VERSION "HNNBNNNYNNNNNNNNNNNNNNNNNNNNNNNNNNNNNNNNNN/4>*%%/4/'%**4NNN///"

NS_ :

BS_:

BU_: Motor DispEngine PedalUnit GearBox Gateway EngineControl Display DashBoard ABS

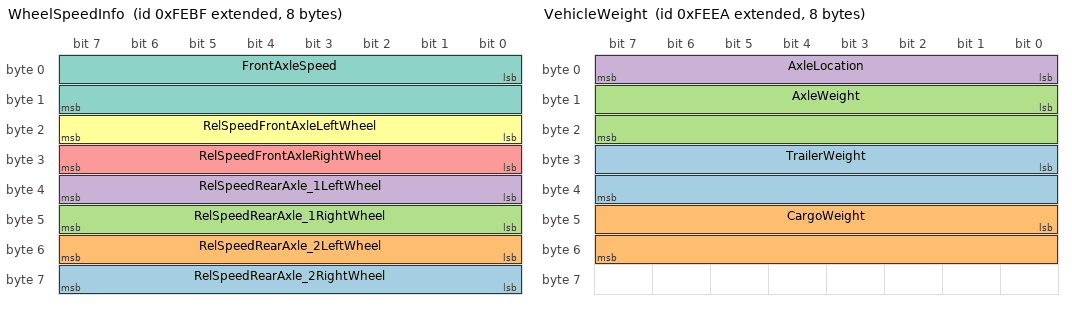
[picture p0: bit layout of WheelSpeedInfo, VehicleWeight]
BO_ 2147548863 WheelSpeedInfo: 8 Vector__XXX
 SG_ RelSpeedRearAxle_2RightWheel : 56|8@1+ (0.0625,-7.8125) [-7.8125|7.8125] "km/h" Vector__XXX
 SG_ RelSpeedRearAxle_2LeftWheel : 48|8@1+ (0.0625,-7.8125) [-7.8125|7.8125] "km/h" Vector__XXX
 SG_ RelSpeedRearAxle_1RightWheel : 40|8@1+ (0.0625,-7.8125) [-7.8125|7.8125] "km/h" Vector__XXX
 SG_ RelSpeedRearAxle_1LeftWheel : 32|8@1+ (0.0625,-7.8125) [-7.8125|7.8125] "km/h" Vector__XXX
 SG_ RelSpeedFrontAxleRightWheel : 24|8@1+ (0.0625,-7.8125) [-7.8125|7.8125] "km/h" Vector__XXX
 SG_ RelSpeedFrontAxleLeftWheel : 16|8@1+ (0.0625,-7.8125) [-7.8125|7.8125] "km/h" Vector__XXX
 SG_ FrontAxleSpeed : 0|16@1+ (0.00390625,0) [0|251] "km/" Vector__XXX

BO_ 2147548927 WaterInFuelInd: 8 Vector__XXX
 SG_ WaterInFuelIndicator : 0|8@1+ (1,0) [0|255] "" Vector__XXX

BO_ 2147548906 VehicleWeight: 8 Vector__XXX
 SG_ TrailerWeight : 24|16@1+ (2,0) [0|128510] "kg" Vector__XXX
 SG_ CargoWeight : 40|16@1+ (2,0) [0|128510] "kg" Vector__XXX
 SG_ AxleWeight : 8|16@1+ (0.5,0) [0|32127.5] "kg" Vector__XXX
 SG_ AxleLocation : 0|8@1+ (1,0) [0|255] "" Vector__XXX

BO_ 2147548915 VehiclePosition: 8 Vector__XXX
 SG_ Longitude : 32|32@1+ (1E-007,-210) [-210|211.108] "degr" Vector__XXX
 SG_ Latitude : 0|32@1+ (1E-007,-210) [-210|211.108] "degr" Vector__XXX

BO_ 2147548903 VehicleHours: 8 Vector__XXX
 SG_ TotalVehicleHours : 0|32@1+ (0.05,0) [0|210554000] "h" Vector__XXX
 SG_ TotalPowerTakeoffHours : 32|32@1+ (0.05,0) [0|210554000] "h" Vector__XXX

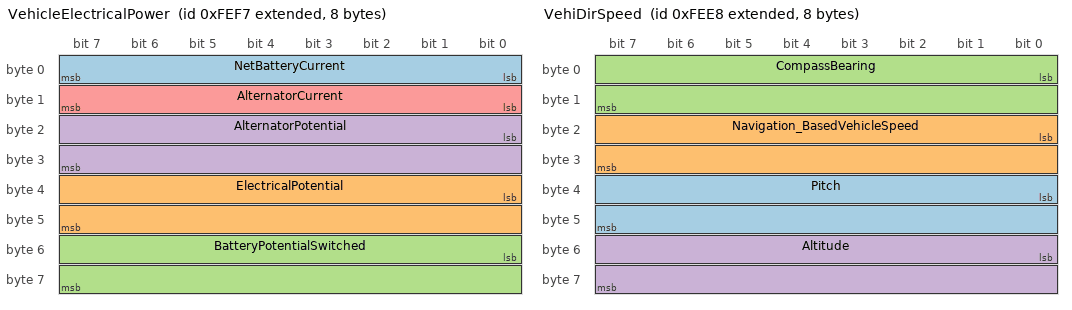
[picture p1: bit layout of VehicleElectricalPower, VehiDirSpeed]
BO_ 2147548919 VehicleElectricalPower: 8 Vector__XXX
 SG_ NetBatteryCurrent : 0|8@1+ (1,-125) [-125|125] "A" Vector__XXX
 SG_ ElectricalPotential : 32|16@1+ (0.05,0) [0|3212.75] "V" Vector__XXX
 SG_ BatteryPotentialSwitched : 48|16@1+ (0.05,0) [0|3212.75] "V" Vector__XXX
 SG_ AlternatorPotential : 16|16@1+ (0.05,0) [0|3212.75] "V" Vector__XXX
 SG_ AlternatorCurrent : 8|8@1+ (1,0) [0|250] "A" Vector__XXX

BO_ 2147548896 VehicleDistance: 8 Vector__XXX
 SG_ TripDistance : 0|32@1+ (0.125,0) [0|526385000] "km" Vector__XXX
 SG_ TotalVehicleDistance : 32|32@1+ (0.125,0) [0|526385000] "km" Vector__XXX

BO_ 2147548904 VehiDirSpeed: 8 Vector__XXX
 SG_ Pitch : 32|16@1+ (0.0078125,-200) [-200|302] "degr" Vector__XXX
 SG_ Navigation_BasedVehicleSpeed : 16|16@1+ (0.00390625,0) [0|251] "km/h" Vector__XXX
 SG_ CompassBearing : 0|16@1+ (0.0078125,0) [0|502] "degr" Vector__XXX
 SG_ Altitude : 48|16@1+ (0.125,0) [0|526385000] "km" Vector__XXX

BO_ 2147548893 Turbocharger: 8 Vector__XXX
 SG_ TurboSpeed : 8|16@1+ (4,0) [0|257020] "rpm" Vector__XXX
 SG_ TurboOilPressure : 0|8@1+ (4,0) [0|1000] "kPa" Vector__XXX

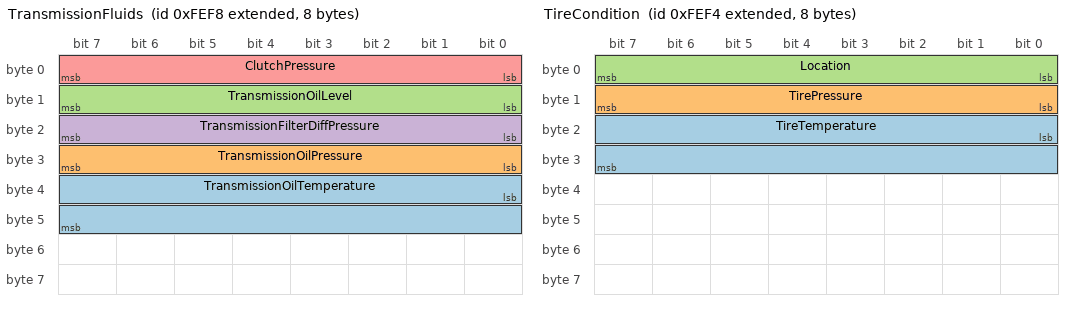
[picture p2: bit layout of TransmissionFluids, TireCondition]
BO_ 2147548920 TransmissionFluids: 8 Vector__XXX
 SG_ TransmissionOilTemperature : 32|16@1+ (0.03125,-273) [-273|1735] "°C" Vector__XXX
 SG_ TransmissionOilPressure : 24|8@1+ (16,0) [0|400] "kPa" Vector__XXX
 SG_ TransmissionOilLevel : 8|8@1+ (0.4,0) [0|100] "%" Vector__XXX
 SG_ TransmissionFilterDiffPressure : 16|8@1+ (2,0) [0|500] "kPa" Vector__XXX
 SG_ ClutchPressure : 0|8@1+ (16,0) [0|400] "kPa" Vector__XXX

BO_ 2147548898 TransmissionConfig: 15 Vector__XXX
 SG_ NumberOfReverseGearRatios : 0|8@1+ (1,0) [0|255] "" Vector__XXX
 SG_ NumberOfForwardGearRatios : 8|8@1+ (1,0) [0|255] "" Vector__XXX
 SG_ MiddleReverseGearRatio : 32|16@1+ (0.001,0) [0|64255] "" Vector__XXX
 SG_ MiddleForwardGearRatio : 88|16@1+ (0.001,0) [0|64255] "" Vector__XXX
 SG_ LowestReverseGearRatio : 48|16@1+ (0.001,0) [0|64255] "" Vector__XXX
 SG_ LowestForwardGearRatio : 104|16@1+ (0.001,0) [0|64255] "" Vector__XXX
 SG_ HighestReverseGearRatio : 16|16@1+ (0.001,0) [0|64255] "" Vector__XXX
 SG_ HighestForwardGearRatio : 72|16@1+ (0.001,0) [0|64255] "" Vector__XXX

BO_ 2147548916 TireCondition: 8 Vector__XXX
 SG_ TireTemperature : 16|16@1+ (0.03125,-273) [-273|1735] "°C" Vector__XXX
 SG_ TirePressure : 8|8@1+ (4,0) [0|1000] "kPa" Vector__XXX
 SG_ Location : 0|8@1+ (1,0) [0|255] "" Vector__XXX

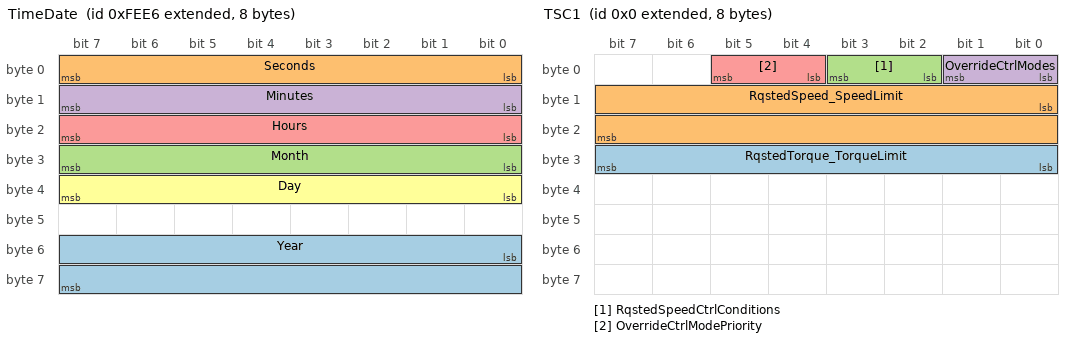
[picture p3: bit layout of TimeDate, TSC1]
BO_ 2147548902 TimeDate: 8 Vector__XXX
 SG_ Year : 48|16@1+ (1,1985) [1985|2235] "year" Vector__XXX
 SG_ Seconds : 0|8@1+ (0.25,0) [0|59.75] "s" Vector__XXX
 SG_ Month : 24|8@1+ (1,0) [1|12] "month" Vector__XXX
 SG_ Minutes : 8|8@1+ (1,0) [0|59] "min" Vector__XXX
 SG_ Hours : 16|8@1+ (1,0) [0|23] "h" Vector__XXX
 SG_ Day : 32|8@1+ (0.25,0) [0.25|31.75] "day" Vector__XXX

BO_ 2147483648 TSC1: 8 Vector__XXX
 SG_ RqstedTorque_TorqueLimit : 24|8@1+ (1,-125) [-125|125] "%" Vector__XXX
 SG_ RqstedSpeed_SpeedLimit : 8|16@1+ (0.125,0) [0|8031.88] "rpm" Vector__XXX
 SG_ RqstedSpeedCtrlConditions : 2|2@1+ (1,0) [0|3] "" Vector__XXX
 SG_ OverrideCtrlModes : 0|2@1+ (1,0) [0|3] "" Vector__XXX
 SG_ OverrideCtrlModePriority : 4|2@1+ (1,0) [0|3] "" Vector__XXX

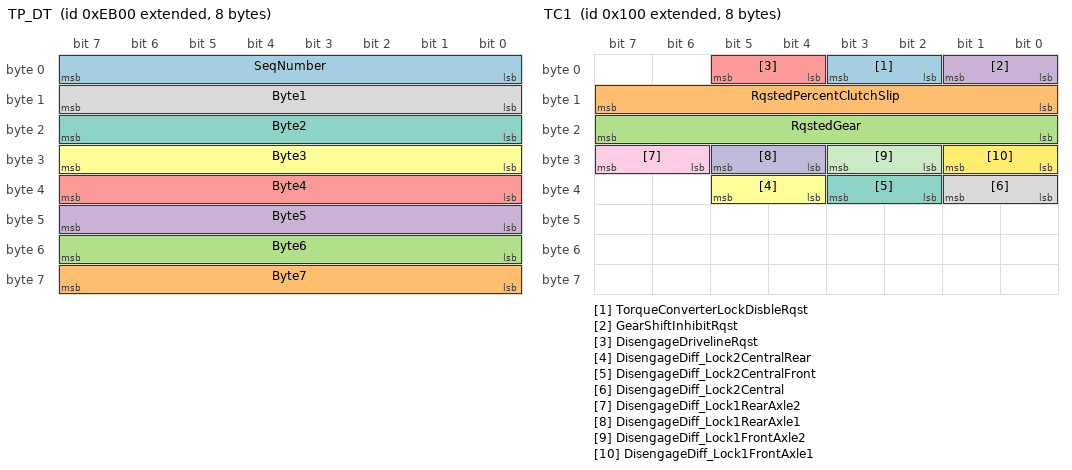
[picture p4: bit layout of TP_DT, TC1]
BO_ 2147543808 TP_DT: 8 Vector__XXX
 SG_ SeqNumber : 0|8@1+ (1,0) [1|255] "" Vector__XXX
 SG_ Byte7 : 56|8@1+ (1,0) [0|255] "" Vector__XXX
 SG_ Byte6 : 48|8@1+ (1,0) [0|255] "" Vector__XXX
 SG_ Byte5 : 40|8@1+ (1,0) [0|255] "" Vector__XXX
 SG_ Byte4 : 32|8@1+ (1,0) [0|255] "" Vector__XXX
 SG_ Byte3 : 24|8@1+ (1,0) [0|255] "" Vector__XXX
 SG_ Byte2 : 16|8@1+ (1,0) [0|255] "" Vector__XXX
 SG_ Byte1 : 8|8@1+ (1,0) [0|255] "" Vector__XXX

BO_ 2147544064 TP_CM: 8 Vector__XXX
 SG_ SendPackets m17 : 8|8@1+ (1,0) [0|255] "" Vector__XXX
 SG_ RtsNoPackets m16 : 24|8@1+ (1,0) [1|255] "" Vector__XXX
 SG_ RtsMsgSize m16 : 8|16@1+ (1,0) [9|1785] "" Vector__XXX
 SG_ PGNumber : 40|24@1+ (1,0) [0|16777200] "" Vector__XXX
 SG_ NextPacket m17 : 16|8@1+ (1,0) [1|255] "" Vector__XXX
 SG_ ControlByte M : 0|8@1+ (1,0) [0|255] "" Vector__XXX
 SG_ BamNoPackets m32 : 24|8@1+ (1,0) [1|255] "" Vector__XXX
 SG_ BamMsgSize m32 : 8|16@1+ (1,0) [9|1785] "" Vector__XXX
 SG_ AckNoPackets m19 : 24|8@1+ (1,0) [1|255] "" Vector__XXX
 SG_ AckMsgSize m19 : 8|16@1+ (1,0) [9|1785] "" Vector__XXX

BO_ 2147483904 TC1: 8 Vector__XXX
 SG_ TorqueConverterLockDisbleRqst : 2|2@1+ (1,0) [0|3] "" Vector__XXX
 SG_ RqstedPercentClutchSlip : 8|8@1+ (0.4,0) [0|100] "%" Vector__XXX
 SG_ RqstedGear : 16|8@1+ (1,-125) [-125|125] "gear" Vector__XXX
 SG_ GearShiftInhibitRqst : 0|2@1+ (1,0) [0|3] "" Vector__XXX
 SG_ DisengageDrivelineRqst : 4|2@1+ (1,0) [0|3] "" Vector__XXX
 SG_ DisengageDiff_Lock2CentralRear : 36|2@1+ (1,0) [0|3] "" Vector__XXX
 SG_ DisengageDiff_Lock2CentralFront : 34|2@1+ (1,0) [0|3] "" Vector__XXX
 SG_ DisengageDiff_Lock2Central : 32|2@1+ (1,0) [0|3] "" Vector__XXX
 SG_ DisengageDiff_Lock1RearAxle2 : 30|2@1+ (1,0) [0|3] "" Vector__XXX
 SG_ DisengageDiff_Lock1RearAxle1 : 28|2@1+ (1,0) [0|3] "" Vector__XXX
 SG_ DisengageDiff_Lock1FrontAxle2 : 26|2@1+ (1,0) [0|3] "" Vector__XXX
 SG_ DisengageDiff_Lock1FrontAxle1 : 24|2@1+ (1,0) [0|3] "" Vector__XXX

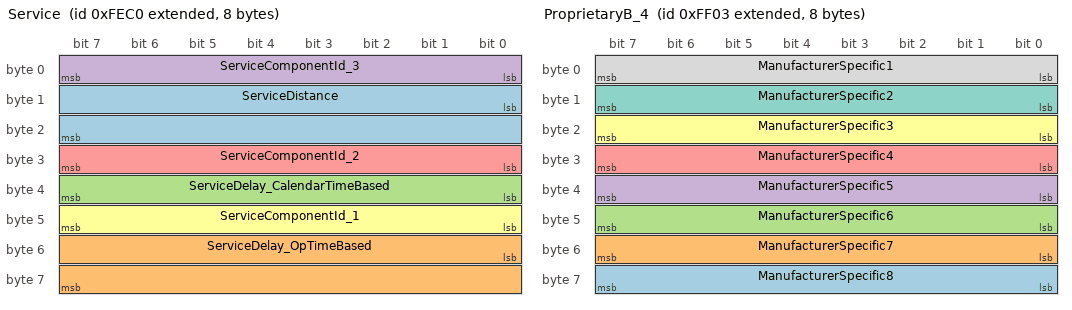
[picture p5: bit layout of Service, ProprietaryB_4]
BO_ 2147548864 Service: 8 Vector__XXX
 SG_ ServiceDistance : 8|16@1+ (5,-160635) [-160635|160640] "km" Vector__XXX
 SG_ ServiceDelay_OpTimeBased : 48|16@1+ (1,-32127) [-32127|32128] "h" Vector__XXX
 SG_ ServiceDelay_CalendarTimeBased : 32|8@1+ (1,-125) [-125|125] "weeks" Vector__XXX
 SG_ ServiceComponentId_3 : 0|8@1+ (1,0) [0|255] "" Vector__XXX
 SG_ ServiceComponentId_2 : 24|8@1+ (1,0) [0|255] "" Vector__XXX
 SG_ ServiceComponentId_1 : 40|8@1+ (1,0) [0|255] "" Vector__XXX

BO_ 2147548923 RetarderFluids: 8 Vector__XXX
 SG_ HydraulicRetarderPressure : 0|8@1+ (16,0) [0|4000] "kPa" Vector__XXX
 SG_ HydraulicRetarderOilTemp : 8|8@1+ (1,-40) [-40|210] "°C" Vector__XXX

BO_ 2147548897 RetarderConfig: 19 Vector__XXX
 SG_ RetarderType : 0|4@1+ (1,0) [0|15] "" Vector__XXX
 SG_ RetarderSpeedAtPt4 : 88|16@1+ (0.125,0) [0|8031.88] "rpm" Vector__XXX
 SG_ RetarderSpeedAtPt3 : 64|16@1+ (0.125,0) [0|8031.88] "rpm" Vector__XXX
 SG_ RetarderSpeedAtPeakTorquePt5 : 112|16@1+ (0.125,0) [0|8031.88] "rpm" Vector__XXX
 SG_ RetarderSpeedAtIdlePt1 : 16|16@1+ (0.125,0) [0|8031.88] "rpm" Vector__XXX
 SG_ RetarderLocation : 4|4@1+ (1,0) [0|15] "" Vector__XXX
 SG_ RetarderCtrlMethod : 8|8@1+ (1,0) [0|250] "step" Vector__XXX
 SG_ ReferenceRetarderTorque : 128|16@1+ (1,0) [0|64255] "Nm" Vector__XXX
 SG_ PercentTorqueAtPt4 : 104|8@1+ (1,-125) [-125|125] "%" Vector__XXX
 SG_ PercentTorqueAtPt3 : 80|8@1+ (1,-125) [-125|125] "%" Vector__XXX
 SG_ PercentTorqueAtPeakTorquePt5 : 144|8@1+ (1,-125) [-125|125] "%" Vector__XXX
 SG_ PercentTorqueAtMaxSpeedPt2 : 56|8@1+ (1,-125) [-125|125] "%" Vector__XXX
 SG_ PercentTorqueAtIdlePt1 : 32|8@1+ (1,-125) [-125|125] "%" Vector__XXX
 SG_ MaximumRetarderSpeedPt2 : 40|16@1+ (0.125,0) [0|8031.88] "rpm" Vector__XXX

BO_ 2147543552 RequestPGN: 3 Vector__XXX
 SG_ RqstedPGN : 0|24@1+ (1,0) [0|16777200] "" Vector__XXX

BO_ 2147548931 ProprietaryB_4: 8 Vector__XXX
 SG_ ManufacturerSpecific8 : 56|8@1+ (1,0) [0|255] "" Vector__XXX
 SG_ ManufacturerSpecific7 : 48|8@1+ (1,0) [0|255] "" Vector__XXX
 SG_ ManufacturerSpecific6 : 40|8@1+ (1,0) [0|255] "" Vector__XXX
 SG_ ManufacturerSpecific5 : 32|8@1+ (1,0) [0|255] "" Vector__XXX
 SG_ ManufacturerSpecific4 : 24|8@1+ (1,0) [0|255] "" Vector__XXX
 SG_ ManufacturerSpecific3 : 16|8@1+ (1,0) [0|255] "" Vector__XXX
 SG_ ManufacturerSpecific2 : 8|8@1+ (1,0) [0|255] "" Vector__XXX
 SG_ ManufacturerSpecific1 : 0|8@1+ (1,0) [0|255] "" Vector__XXX

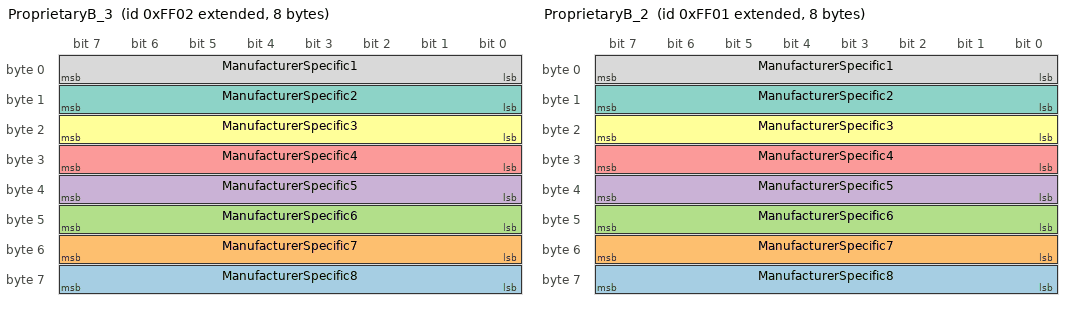
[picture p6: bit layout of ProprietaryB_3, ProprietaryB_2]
BO_ 2147548930 ProprietaryB_3: 8 Vector__XXX
 SG_ ManufacturerSpecific8 : 56|8@1+ (1,0) [0|255] "" Vector__XXX
 SG_ ManufacturerSpecific7 : 48|8@1+ (1,0) [0|255] "" Vector__XXX
 SG_ ManufacturerSpecific6 : 40|8@1+ (1,0) [0|255] "" Vector__XXX
 SG_ ManufacturerSpecific5 : 32|8@1+ (1,0) [0|255] "" Vector__XXX
 SG_ ManufacturerSpecific4 : 24|8@1+ (1,0) [0|255] "" Vector__XXX
 SG_ ManufacturerSpecific3 : 16|8@1+ (1,0) [0|255] "" Vector__XXX
 SG_ ManufacturerSpecific2 : 8|8@1+ (1,0) [0|255] "" Vector__XXX
 SG_ ManufacturerSpecific1 : 0|8@1+ (1,0) [0|255] "" Vector__XXX

BO_ 2147548929 ProprietaryB_2: 8 Vector__XXX
 SG_ ManufacturerSpecific8 : 56|8@1+ (1,0) [0|255] "" Vector__XXX
 SG_ ManufacturerSpecific7 : 48|8@1+ (1,0) [0|255] "" Vector__XXX
 SG_ ManufacturerSpecific6 : 40|8@1+ (1,0) [0|255] "" Vector__XXX
 SG_ ManufacturerSpecific5 : 32|8@1+ (1,0) [0|255] "" Vector__XXX
 SG_ ManufacturerSpecific4 : 24|8@1+ (1,0) [0|255] "" Vector__XXX
 SG_ ManufacturerSpecific3 : 16|8@1+ (1,0) [0|255] "" Vector__XXX
 SG_ ManufacturerSpecific2 : 8|8@1+ (1,0) [0|255] "" Vector__XXX
 SG_ ManufacturerSpecific1 : 0|8@1+ (1,0) [0|255] "" Vector__XXX

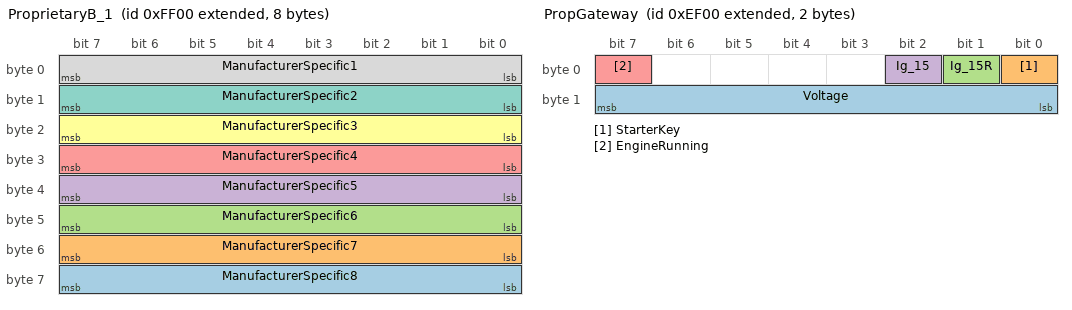
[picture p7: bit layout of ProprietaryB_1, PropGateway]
BO_ 2147548928 ProprietaryB_1: 8 Vector__XXX
 SG_ ManufacturerSpecific8 : 56|8@1+ (1,0) [0|255] "" Vector__XXX
 SG_ ManufacturerSpecific7 : 48|8@1+ (1,0) [0|255] "" Vector__XXX
 SG_ ManufacturerSpecific6 : 40|8@1+ (1,0) [0|255] "" Vector__XXX
 SG_ ManufacturerSpecific5 : 32|8@1+ (1,0) [0|255] "" Vector__XXX
 SG_ ManufacturerSpecific4 : 24|8@1+ (1,0) [0|255] "" Vector__XXX
 SG_ ManufacturerSpecific3 : 16|8@1+ (1,0) [0|255] "" Vector__XXX
 SG_ ManufacturerSpecific2 : 8|8@1+ (1,0) [0|255] "" Vector__XXX
 SG_ ManufacturerSpecific1 : 0|8@1+ (1,0) [0|255] "" Vector__XXX

BO_ 2147544832 PropGateway: 2 Vector__XXX
 SG_ Voltage : 8|8@1+ (0.1,0) [50|180] "V" Vector__XXX
 SG_ StarterKey : 0|1@1+ (1,0) [0|1] "" Vector__XXX
 SG_ Ig_15R : 1|1@1+ (1,0) [0|0] "" Vector__XXX
 SG_ Ig_15 : 2|1@1+ (1,0) [0|0] "" Vector__XXX
 SG_ EngineRunning : 7|1@1+ (1,0) [0|0] "" Vector__XXX

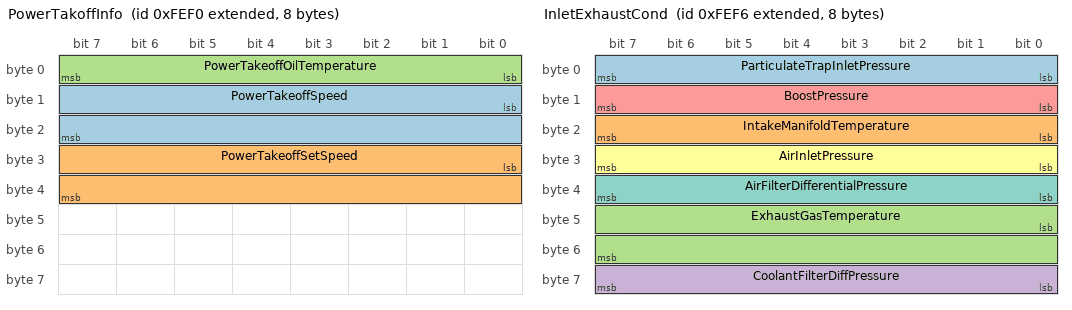
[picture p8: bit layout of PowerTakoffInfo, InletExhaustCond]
BO_ 2147548912 PowerTakoffInfo: 8 Vector__XXX
 SG_ PowerTakeoffSpeed : 8|16@1+ (0.125,0) [0|8031.88] "rpm" Vector__XXX
 SG_ PowerTakeoffSetSpeed : 24|16@1+ (0.125,0) [0|8031.88] "rpm" Vector__XXX
 SG_ PowerTakeoffOilTemperature : 0|8@1+ (1,-40) [-40|210] "°C" Vector__XXX

BO_ 2147548918 InletExhaustCond: 8 Vector__XXX
 SG_ ParticulateTrapInletPressure : 0|8@1+ (0.5,0) [0|125] "kPa" Vector__XXX
 SG_ IntakeManifoldTemperature : 16|8@1+ (1,-40) [-40|210] "°C" Vector__XXX
 SG_ ExhaustGasTemperature : 40|16@1+ (0.03125,-273) [-273|1735] "°C" Vector__XXX
 SG_ CoolantFilterDiffPressure : 56|8@1+ (0.5,0) [0|125] "kPa" Vector__XXX
 SG_ BoostPressure : 8|8@1+ (2,0) [0|500] "kPa" Vector__XXX
 SG_ AirInletPressure : 24|8@1+ (2,0) [0|500] "kPa" Vector__XXX
 SG_ AirFilterDifferentialPressure : 32|8@1+ (0.05,0) [0|12.5] "kPa" Vector__XXX

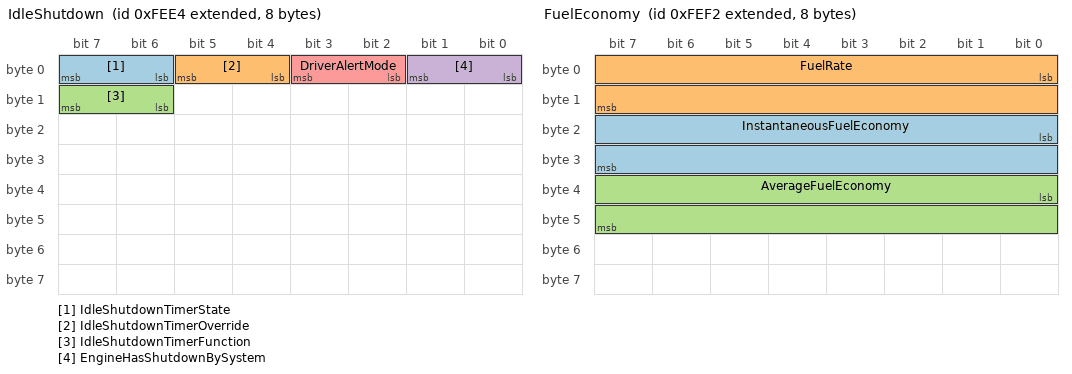
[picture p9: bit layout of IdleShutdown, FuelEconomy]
BO_ 2147548900 IdleShutdown: 8 Vector__XXX
 SG_ IdleShutdownTimerState : 6|2@1+ (1,0) [0|3] "" Vector__XXX
 SG_ IdleShutdownTimerOverride : 4|2@1+ (1,0) [0|3] "" Vector__XXX
 SG_ IdleShutdownTimerFunction : 14|2@1+ (1,0) [0|3] "" Vector__XXX
 SG_ EngineHasShutdownBySystem : 0|2@1+ (1,0) [0|3] "" Vector__XXX
 SG_ DriverAlertMode : 2|2@1+ (1,0) [0|3] "" Vector__XXX

BO_ 2147548892 IdleOperation: 8 Vector__XXX
 SG_ TotalIdleHours : 32|32@1+ (0.05,0) [0|210554000] "h" Vector__XXX
 SG_ TotalIdleFuelUsed : 0|32@1+ (0.5,0) [0|2105540000] "L" Vector__XXX

BO_ 2147548865 HiResVehicleDist: 8 Vector__XXX
 SG_ HighResolTripDistance : 32|32@1+ (5,0) [0|21055400] "km" Vector__XXX
 SG_ HighResolTotalVehicleDistance : 0|32@1+ (5,0) [0|21055400] "km" Vector__XXX

BO_ 2147548914 FuelEconomy: 8 Vector__XXX
 SG_ InstantaneousFuelEconomy : 16|16@1+ (0.00195312,0) [0|125.5] "km" Vector__XXX
 SG_ FuelRate : 0|16@1+ (0.05,0) [0|3212.75] "L/h" Vector__XXX
 SG_ AverageFuelEconomy : 32|16@1+ (0.00195312,0) [0|125.5] "km" Vector__XXX

BO_ 2147548905 FuelConsumption: 8 Vector__XXX
 SG_ TripFuel : 0|32@1+ (0.5,0) [0|2105540000] "L" Vector__XXX
 SG_ TotalFuelUsed : 32|32@1+ (0.5,0) [0|2105540000] "L" Vector__XXX

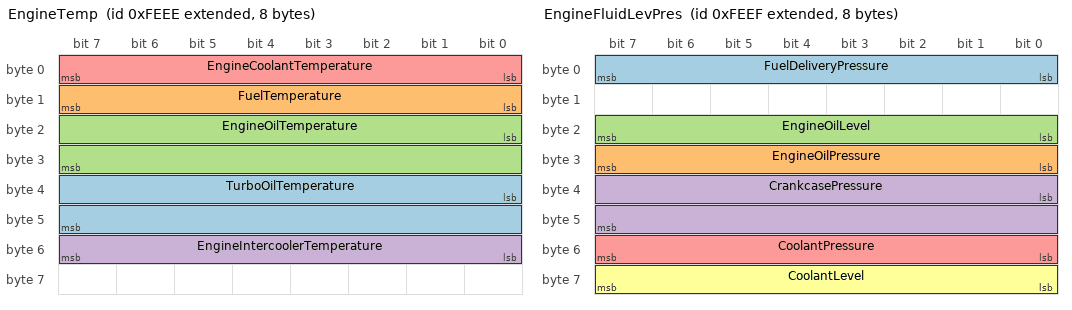
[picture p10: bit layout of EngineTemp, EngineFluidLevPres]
BO_ 2147548910 EngineTemp: 8 Vector__XXX
 SG_ TurboOilTemperature : 32|16@1+ (0.03125,-273) [-273|1735] "°C" Vector__XXX
 SG_ FuelTemperature : 8|8@1+ (1,-40) [-40|210] "°C" Vector__XXX
 SG_ EngineOilTemperature : 16|16@1+ (0.03125,-273) [-273|1735] "°C" Vector__XXX
 SG_ EngineIntercoolerTemperature : 48|8@1+ (1,-40) [-40|210] "°C" Vector__XXX
 SG_ EngineCoolantTemperature : 0|8@1+ (1,-40) [-40|210] "°C" Vector__XXX

BO_ 2147548901 EngineHoursRevolutions: 8 Vector__XXX
 SG_ TotalEngineRevolutions : 32|32@1+ (1000,0) [0|4.21108E+012] "r" Vector__XXX
 SG_ TotalEngineHours : 0|32@1+ (0.05,0) [0|210554000] "h" Vector__XXX

BO_ 2147548891 EngineFluidLevPres2: 8 Vector__XXX
 SG_ InjectorMeteringRailPressure : 16|16@1+ (0.00390625,0) [0|251] "MPa" Vector__XXX
 SG_ InjectionCtrlPressure : 0|16@1+ (0.00390625,0) [0|251] "MPa" Vector__XXX

BO_ 2147548911 EngineFluidLevPres: 8 Vector__XXX
 SG_ FuelDeliveryPressure : 0|8@1+ (4,0) [0|1000] "kPa" Vector__XXX
 SG_ EngineOilPressure : 24|8@1+ (4,0) [0|1000] "kPa" Vector__XXX
 SG_ EngineOilLevel : 16|8@1+ (0.4,0) [0|100] "%" Vector__XXX
 SG_ CrankcasePressure : 32|16@1+ (7812.5,-250) [-250|251.99] "kPa" Vector__XXX
 SG_ CoolantPressure : 48|8@1+ (2,0) [0|500] "kPa" Vector__XXX
 SG_ CoolantLevel : 56|8@1+ (0.4,0) [0|100] "%" Vector__XXX

BO_ 2147548899 EngineConfig: 28 Vector__XXX
 SG_ RqstedTorqueCtrlRangeUpperLimit : 216|8@1+ (1,-125) [-125|125] "%" Vector__XXX
 SG_ RqstedTorqueCtrlRangeLowerLimit : 208|8@1+ (1,-125) [-125|125] "%" Vector__XXX
 SG_ RqstedSpeedCtrlRangeUpperLimit : 200|8@1+ (10,0) [0|2500] "rpm" Vector__XXX
 SG_ RqstedSpeedCtrlRangeLowerLimit : 192|8@1+ (10,0) [0|2500] "rpm" Vector__XXX
 SG_ ReferenceEngineTorque : 152|16@1+ (1,0) [0|64255] "Nm" Vector__XXX
 SG_ PercentTorqueAtPt5 : 112|8@1+ (1,-125) [-125|125] "%" Vector__XXX
 SG_ PercentTorqueAtPt4 : 88|8@1+ (1,-125) [-125|125] "%" Vector__XXX
 SG_ PercentTorqueAtPt3 : 64|8@1+ (1,-125) [-125|125] "%" Vector__XXX
 SG_ PercentTorqueAtPt2 : 40|8@1+ (1,-125) [-125|125] "%" Vector__XXX
 SG_ PercentTorqueAtIdlePt1 : 16|8@1+ (1,-125) [-125|125] "%" Vector__XXX
 SG_ MaxMomentEngineOvrwrtTimeLimit : 184|8@1+ (0.1,0) [0|25] "s" Vector__XXX
 SG_ MaxMomentEngineOvrwrtSpeedPt7 : 168|16@1+ (0.125,0) [0|8031.88] "rpm" Vector__XXX
 SG_ GainOfEndspeedGovernor : 136|16@1+ (0.0007813,0) [0|50.2] "%" Vector__XXX
 SG_ EngineSpeedAtPt5 : 96|16@1+ (0.125,0) [0|8031.88] "rpm" Vector__XXX
 SG_ EngineSpeedAtPt4 : 72|16@1+ (0.125,0) [0|8031.88] "rpm" Vector__XXX
 SG_ EngineSpeedAtPt3 : 48|16@1+ (0.125,0) [0|8031.88] "rpm" Vector__XXX
 SG_ EngineSpeedAtPt2 : 24|16@1+ (0.125,0) [0|8031.88] "rpm" Vector__XXX
 SG_ EngineSpeedAtIdlePt1 : 0|16@1+ (0.125,0) [0|8031.88] "rpm" Vector__XXX
 SG_ EngineSpeedAtHighIdlePt6 : 120|16@1+ (0.125,0) [0|8031.88] "rpm" Vector__XXX

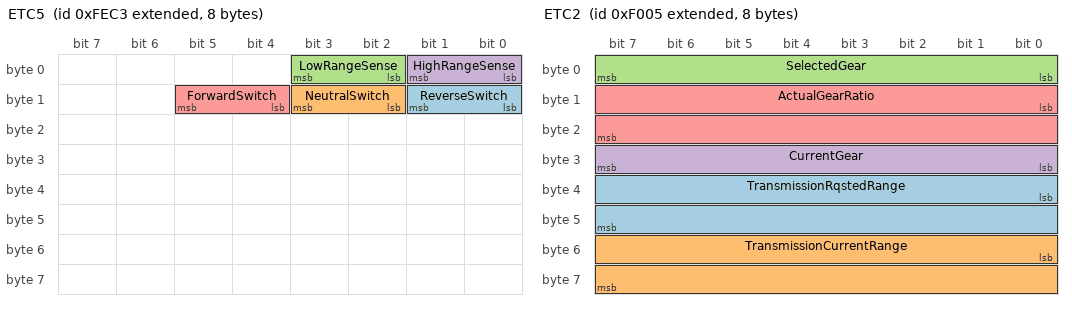
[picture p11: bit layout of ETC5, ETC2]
BO_ 2147548867 ETC5: 8 Vector__XXX
 SG_ ReverseSwitch : 8|2@1+ (1,0) [0|3] "" Vector__XXX
 SG_ NeutralSwitch : 10|2@1+ (1,0) [0|3] "" Vector__XXX
 SG_ LowRangeSense : 2|2@1+ (1,0) [0|3] "" Vector__XXX
 SG_ HighRangeSense : 0|2@1+ (1,0) [0|3] "" Vector__XXX
 SG_ ForwardSwitch : 12|2@1+ (1,0) [0|3] "" Vector__XXX

BO_ 2147548869 ETC4: 8 Vector__XXX
 SG_ TransmissionSynchroClutchVal : 0|8@1+ (0.4,0) [0|100] "%" Vector__XXX
 SG_ TransmissionSynchroBrakeVal : 8|8@1+ (0.4,0) [0|100] "%" Vector__XXX

BO_ 2147548871 ETC3: 8 Vector__XXX
 SG_ SplitterIndirectActuator : 38|2@1+ (1,0) [0|3] "" Vector__XXX
 SG_ SplitterDirectActuator : 36|2@1+ (1,0) [0|3] "" Vector__XXX
 SG_ ShiftFingerRailPosition : 8|8@1+ (0.4,0) [0|100] "%" Vector__XXX
 SG_ ShiftFingerGearPosition : 0|8@1+ (0.4,0) [0|100] "%" Vector__XXX
 SG_ RangeLowActuator : 34|2@1+ (1,0) [0|3] "" Vector__XXX
 SG_ RangeHighActuator : 32|2@1+ (1,0) [0|3] "" Vector__XXX
 SG_ RailActuator_2 : 28|2@1+ (1,0) [0|3] "" Vector__XXX
 SG_ RailActuator_1 : 24|2@1+ (1,0) [0|3] "" Vector__XXX
 SG_ NeutralIndicator : 16|2@1+ (1,0) [0|3] "" Vector__XXX
 SG_ LockupClutchActuator : 42|2@1+ (1,0) [0|3] "" Vector__XXX
 SG_ InertiaBrakeActuator : 46|2@1+ (1,0) [0|3] "" Vector__XXX
 SG_ GearActuator_2 : 30|2@1+ (1,0) [0|3] "" Vector__XXX
 SG_ GearActuator_1 : 26|2@1+ (1,0) [0|3] "" Vector__XXX
 SG_ EngagementIndicator : 18|2@1+ (1,0) [0|3] "" Vector__XXX
 SG_ DefuelActuator : 44|2@1+ (1,0) [0|3] "" Vector__XXX
 SG_ ClutchActuator : 40|2@1+ (1,0) [0|3] "" Vector__XXX
 SG_ CenterRailIndicator : 20|2@1+ (1,0) [0|3] "" Vector__XXX

BO_ 2147545093 ETC2: 8 Vector__XXX
 SG_ TransmissionRqstedRange : 32|16@1+ (1,0) [0|65535] "" Vector__XXX
 SG_ TransmissionCurrentRange : 48|16@1+ (1,0) [0|65535] "" Vector__XXX
 SG_ SelectedGear : 0|8@1+ (1,-125) [-125|125] "" Vector__XXX
 SG_ CurrentGear : 24|8@1+ (1,-125) [-125|125] "" Vector__XXX
 SG_ ActualGearRatio : 8|16@1+ (0.001,0) [0|64.255] "" Vector__XXX

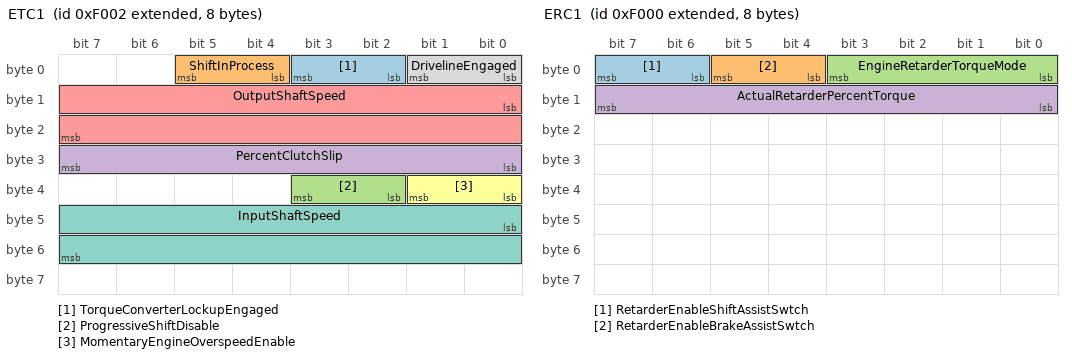
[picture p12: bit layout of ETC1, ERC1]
BO_ 2147545090 ETC1: 8 Vector__XXX
 SG_ TorqueConverterLockupEngaged : 2|2@1+ (1,0) [0|3] "" Vector__XXX
 SG_ ShiftInProcess : 4|2@1+ (1,0) [0|3] "" Vector__XXX
 SG_ ProgressiveShiftDisable : 34|2@1+ (1,0) [0|3] "" Vector__XXX
 SG_ PercentClutchSlip : 24|8@1+ (0.4,0) [0|100] "%" Vector__XXX
 SG_ OutputShaftSpeed : 8|16@1+ (0.125,0) [0|8031.88] "rpm" Vector__XXX
 SG_ MomentaryEngineOverspeedEnable : 32|2@1+ (1,0) [0|3] "" Vector__XXX
 SG_ InputShaftSpeed : 40|16@1+ (0.125,0) [0|8031.88] "rpm" Vector__XXX
 SG_ DrivelineEngaged : 0|2@1+ (1,0) [0|3] "" Vector__XXX

BO_ 2147548866 ERC2: 8 Vector__XXX
 SG_ TransmissionOutputRetarder : 0|2@1+ (1,0) [0|3] "" Vector__XXX

BO_ 2147545088 ERC1: 8 Vector__XXX
 SG_ RetarderEnableShiftAssistSwtch : 6|2@1+ (1,0) [0|3] "" Vector__XXX
 SG_ RetarderEnableBrakeAssistSwtch : 4|2@1+ (1,0) [0|3] "" Vector__XXX
 SG_ EngineRetarderTorqueMode : 0|4@1+ (1,0) [0|15] "" Vector__XXX
 SG_ ActualRetarderPercentTorque : 8|8@1+ (1,-125) [-125|125] "%" Vector__XXX

BO_ 2147548862 EEC4: 8 Vector__XXX
 SG_ RatedEngineSpeed : 16|16@1+ (0.125,0) [0|8031.88] "rpm" Vector__XXX
 SG_ RatedEnginePower : 0|16@1+ (0.5,0) [0|32127.5] "kW" Vector__XXX

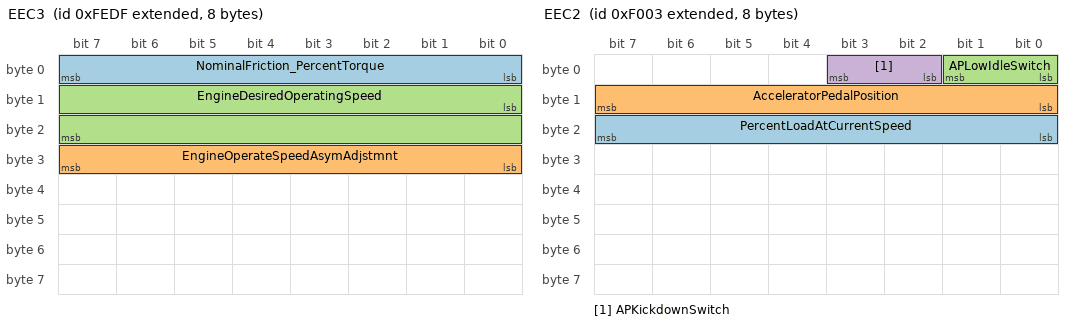
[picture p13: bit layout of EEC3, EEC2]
BO_ 2147548895 EEC3: 8 Vector__XXX
 SG_ NominalFriction_PercentTorque : 0|8@1+ (1,-125) [-125|125] "%" Vector__XXX
 SG_ EngineOperateSpeedAsymAdjstmnt : 24|8@1+ (1,0) [0|250] "" Vector__XXX
 SG_ EngineDesiredOperatingSpeed : 8|16@1+ (0.125,0) [0|8031.88] "rpm" Vector__XXX

BO_ 2147545091 EEC2: 8 Vector__XXX
 SG_ PercentLoadAtCurrentSpeed : 16|8@1+ (1,0) [0|125] "%" Vector__XXX
 SG_ AcceleratorPedalPosition : 8|8@1+ (1,0) [0|125] "%" Vector__XXX
 SG_ APLowIdleSwitch : 0|2@1+ (1,0) [0|3] "" Vector__XXX
 SG_ APKickdownSwitch : 2|2@1+ (1,0) [0|3] "" Vector__XXX

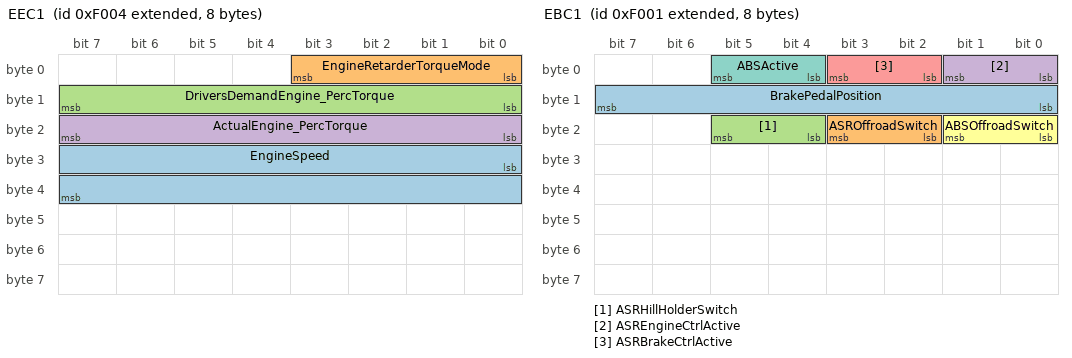
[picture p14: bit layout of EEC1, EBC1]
BO_ 2147545092 EEC1: 8 Vector__XXX
 SG_ EngineSpeed : 24|16@1+ (0.125,0) [0|8031.88] "rpm" Vector__XXX
 SG_ EngineRetarderTorqueMode : 0|4@1+ (1,0) [0|15] "" Vector__XXX
 SG_ DriversDemandEngine_PercTorque : 8|8@1+ (1,-125) [-125|125] "%" Vector__XXX
 SG_ ActualEngine_PercTorque : 16|8@1+ (1,-125) [-125|125] "%" Vector__XXX

BO_ 2147545089 EBC1: 8 Vector__XXX
 SG_ BrakePedalPosition : 8|8@1+ (0.4,0) [0|100] "%" Vector__XXX
 SG_ ASROffroadSwitch : 18|2@1+ (1,0) [0|3] "" Vector__XXX
 SG_ ASRHillHolderSwitch : 20|2@1+ (1,0) [0|3] "" Vector__XXX
 SG_ ASREngineCtrlActive : 0|2@1+ (1,0) [0|3] "" Vector__XXX
 SG_ ASRBrakeCtrlActive : 2|2@1+ (1,0) [0|3] "" Vector__XXX
 SG_ ABSOffroadSwitch : 16|2@1+ (1,0) [0|3] "" Vector__XXX
 SG_ ABSActive : 4|2@1+ (1,0) [0|3] "" Vector__XXX

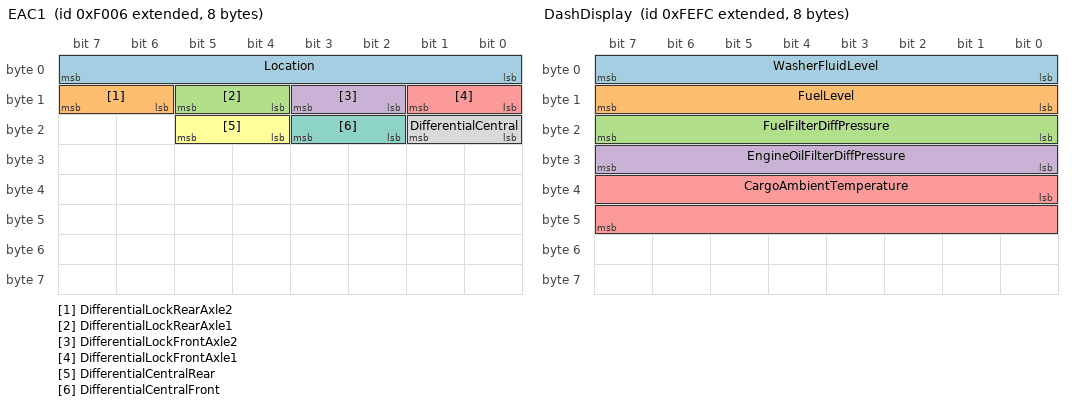
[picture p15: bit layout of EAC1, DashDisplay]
BO_ 2147545094 EAC1: 8 Vector__XXX
 SG_ Location : 0|8@1+ (1,0) [0|255] "" Vector__XXX
 SG_ DifferentialLockRearAxle2 : 14|2@1+ (1,0) [0|3] "" Vector__XXX
 SG_ DifferentialLockRearAxle1 : 12|2@1+ (1,0) [0|3] "" Vector__XXX
 SG_ DifferentialLockFrontAxle2 : 10|2@1+ (1,0) [0|3] "" Vector__XXX
 SG_ DifferentialLockFrontAxle1 : 8|2@1+ (1,0) [0|3] "" Vector__XXX
 SG_ DifferentialCentralRear : 20|2@1+ (1,0) [0|3] "" Vector__XXX
 SG_ DifferentialCentralFront : 18|2@1+ (1,0) [0|3] "" Vector__XXX
 SG_ DifferentialCentral : 16|2@1+ (1,0) [0|3] "" Vector__XXX

BO_ 2147548924 DashDisplay: 8 Vector__XXX
 SG_ WasherFluidLevel : 0|8@1+ (0.4,0) [0|100] "%" Vector__XXX
 SG_ FuelLevel : 8|8@1+ (0.4,0) [0|100] "%" Vector__XXX
 SG_ FuelFilterDiffPressure : 16|8@1+ (2,0) [0|500] "kPa" Vector__XXX
 SG_ EngineOilFilterDiffPressure : 24|8@1+ (0.5,0) [0|125] "kPa" Vector__XXX
 SG_ CargoAmbientTemperature : 32|16@1+ (0.03125,-273) [-273|1735] "°C" Vector__XXX

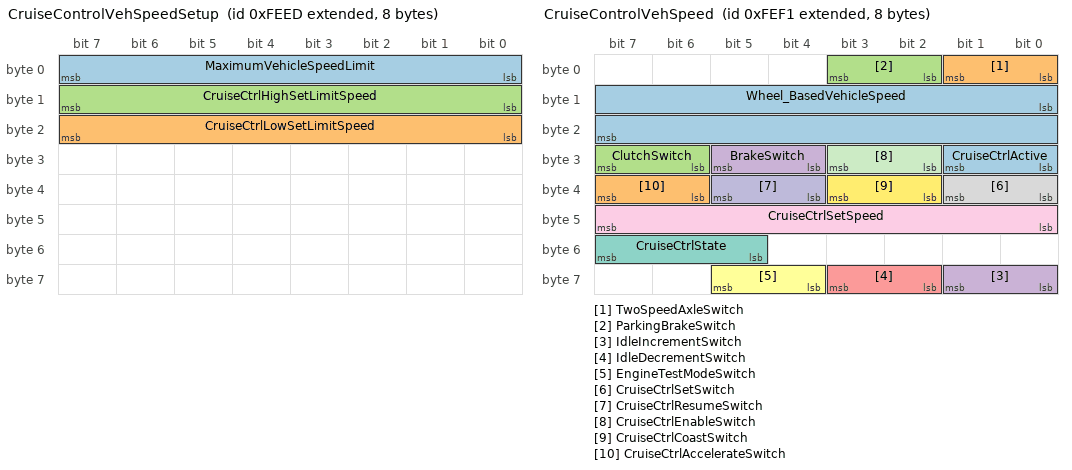
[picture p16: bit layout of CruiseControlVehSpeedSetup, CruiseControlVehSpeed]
BO_ 2147548909 CruiseControlVehSpeedSetup: 8 Vector__XXX
 SG_ MaximumVehicleSpeedLimit : 0|8@1+ (1,0) [0|250] "km/h" Vector__XXX
 SG_ CruiseCtrlLowSetLimitSpeed : 16|8@1+ (1,0) [0|250] "km/h" Vector__XXX
 SG_ CruiseCtrlHighSetLimitSpeed : 8|8@1+ (1,0) [0|250] "km/h" Vector__XXX

BO_ 2147548913 CruiseControlVehSpeed: 8 Vector__XXX
 SG_ Wheel_BasedVehicleSpeed : 8|16@1+ (0.00390625,0) [0|251] "km/" Vector__XXX
 SG_ TwoSpeedAxleSwitch : 0|2@1+ (1,0) [0|3] "" Vector__XXX
 SG_ ParkingBrakeSwitch : 2|2@1+ (1,0) [0|3] "" Vector__XXX
 SG_ IdleIncrementSwitch : 56|2@1+ (1,0) [0|3] "" Vector__XXX
 SG_ IdleDecrementSwitch : 58|2@1+ (1,0) [0|3] "" Vector__XXX
 SG_ EngineTestModeSwitch : 60|2@1+ (1,0) [0|3] "" Vector__XXX
 SG_ CruiseCtrlState : 53|3@1+ (1,0) [0|7] "" Vector__XXX
 SG_ CruiseCtrlSetSwitch : 32|2@1+ (1,0) [0|3] "" Vector__XXX
 SG_ CruiseCtrlSetSpeed : 40|8@1+ (1,0) [0|250] "km/h" Vector__XXX
 SG_ CruiseCtrlResumeSwitch : 36|2@1+ (1,0) [0|3] "" Vector__XXX
 SG_ CruiseCtrlEnableSwitch : 26|2@1+ (1,0) [0|3] "" Vector__XXX
 SG_ CruiseCtrlCoastSwitch : 34|2@1+ (1,0) [0|3] "" Vector__XXX
 SG_ CruiseCtrlActive : 24|2@1+ (1,0) [0|3] "" Vector__XXX
 SG_ CruiseCtrlAccelerateSwitch : 38|2@1+ (1,0) [0|3] "" Vector__XXX
 SG_ ClutchSwitch : 30|2@1+ (1,0) [0|3] "" Vector__XXX
 SG_ BrakeSwitch : 28|2@1+ (1,0) [0|3] "" Vector__XXX

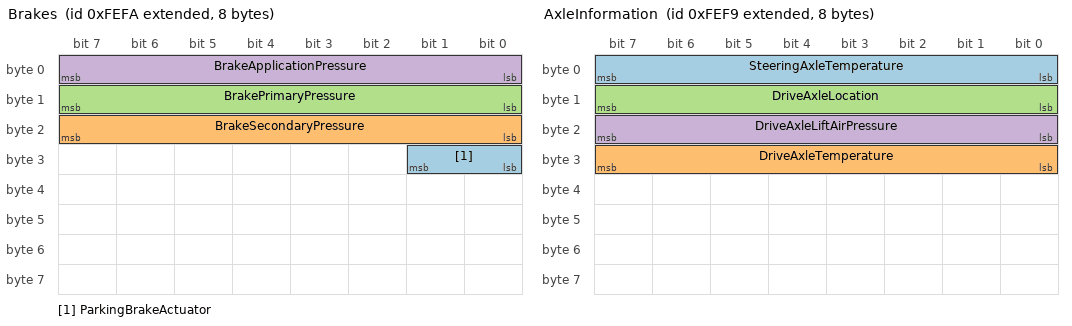
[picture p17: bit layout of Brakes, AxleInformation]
BO_ 2147548922 Brakes: 8 Vector__XXX
 SG_ ParkingBrakeActuator : 24|2@1+ (1,0) [0|3] "" Vector__XXX
 SG_ BrakeSecondaryPressure : 16|8@1+ (4,0) [0|1000] "kPa" Vector__XXX
 SG_ BrakePrimaryPressure : 8|8@1+ (4,0) [0|1000] "kPa" Vector__XXX
 SG_ BrakeApplicationPressure : 0|8@1+ (4,0) [0|1000] "kPa" Vector__XXX

BO_ 2147548921 AxleInformation: 8 Vector__XXX
 SG_ SteeringAxleTemperature : 0|8@1+ (1,-40) [-40|210] "°C" Vector__XXX
 SG_ DriveAxleTemperature : 24|8@1+ (0.001,0) [0|64255] "bit" Vector__XXX
 SG_ DriveAxleLocation : 8|8@1+ (1,0) [0|255] "" Vector__XXX
 SG_ DriveAxleLiftAirPressure : 16|8@1+ (4,0) [0|1000] "kPa" Vector__XXX

BO_ 2147548926 AuxWaterPumpPressure: 8 Vector__XXX
 SG_ AuxiliaryPumpPressure : 0|8@1+ (16,0) [0|4000] "kPa" Vector__XXX

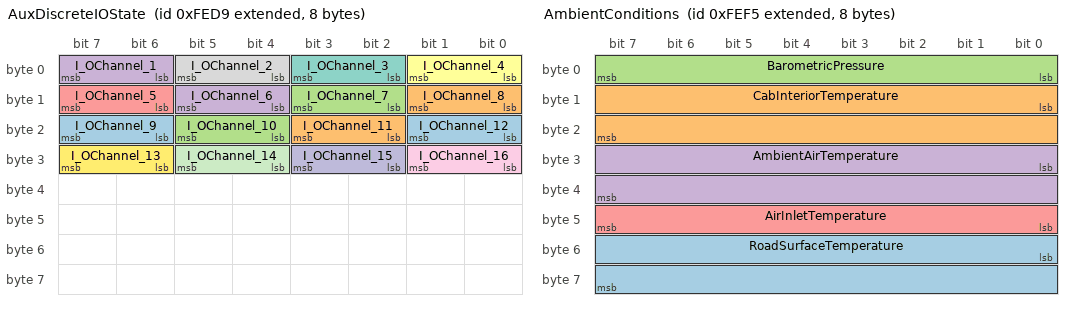
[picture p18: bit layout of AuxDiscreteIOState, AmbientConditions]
BO_ 2147548889 AuxDiscreteIOState: 8 Vector__XXX
 SG_ I_OChannel_9 : 22|2@1+ (1,0) [0|3] "" Vector__XXX
 SG_ I_OChannel_8 : 8|2@1+ (1,0) [0|3] "" Vector__XXX
 SG_ I_OChannel_7 : 10|2@1+ (1,0) [0|3] "" Vector__XXX
 SG_ I_OChannel_6 : 12|2@1+ (1,0) [0|3] "" Vector__XXX
 SG_ I_OChannel_5 : 14|2@1+ (1,0) [0|3] "" Vector__XXX
 SG_ I_OChannel_4 : 0|2@1+ (1,0) [0|3] "" Vector__XXX
 SG_ I_OChannel_3 : 2|2@1+ (1,0) [0|3] "" Vector__XXX
 SG_ I_OChannel_2 : 4|2@1+ (1,0) [0|3] "" Vector__XXX
 SG_ I_OChannel_16 : 24|2@1+ (1,0) [0|3] "" Vector__XXX
 SG_ I_OChannel_15 : 26|2@1+ (1,0) [0|3] "" Vector__XXX
 SG_ I_OChannel_14 : 28|2@1+ (1,0) [0|3] "" Vector__XXX
 SG_ I_OChannel_13 : 30|2@1+ (1,0) [0|3] "" Vector__XXX
 SG_ I_OChannel_12 : 16|2@1+ (1,0) [0|3] "" Vector__XXX
 SG_ I_OChannel_11 : 18|2@1+ (1,0) [0|3] "" Vector__XXX
 SG_ I_OChannel_10 : 20|2@1+ (1,0) [0|3] "" Vector__XXX
 SG_ I_OChannel_1 : 6|2@1+ (1,0) [0|3] "" Vector__XXX

BO_ 2147548917 AmbientConditions: 8 Vector__XXX
 SG_ RoadSurfaceTemperature : 48|16@1+ (0.03125,-273) [273|1735] "°C" Vector__XXX
 SG_ CabInteriorTemperature : 8|16@1+ (0.03125,-273) [273|1735] "°C" Vector__XXX
 SG_ BarometricPressure : 0|8@1+ (0.5,0) [0|125] "kPa" Vector__XXX
 SG_ AmbientAirTemperature : 24|16@1+ (0.03125,-273) [-273|1735] "°C" Vector__XXX
 SG_ AirInletTemperature : 40|8@1+ (1,-40) [-40|210] "°C" Vector__XXX

BO_ 2147548885 AlternatorSpeed: 8 Vector__XXX
 SG_ AlternatorSpeed : 0|16@1+ (0.5,0) [0|32127.5] "rpm" Vector__XXX

BO_ 2147548925 AlternateFuel_1: 8 Vector__XXX
 SG_ GasSupplyPressure : 8|16@1+ (0.5,0) [0|32127.5] "kPa" Vector__XXX
 SG_ BlowerBypassValvePosition : 0|8@1+ (0.4,0) [0|100] "%" Vector__XXX

BO_ 2147548894 AirStartPressure: 8 Vector__XXX
 SG_ AirStartPressure : 0|8@1+ (4,0) [0|1000] "kPa" Vector__XXX

BO_ 2147543040 ACKN: 8 Vector__XXX
 SG_ PGN : 40|24@1+ (1,0) [0|16777200] "" Vector__XXX
 SG_ CtrlByte : 0|8@1+ (1,0) [0|255] "" Vector__XXX

EV_ evParkBrake: 0 [0|1] "" 0 1 DUMMY_NODE_VECTOR1  EngineControl;

EV_ evSpeed: 1 [0|0] "" 0 2 DUMMY_NODE_VECTOR0 Vector__XXX;

EV_ evShowTemp: 1 [0|70] "" 0 3 DUMMY_NODE_VECTOR0 Vector__XXX;

EV_ evShowSpeed: 1 [0|100] "" 0 4 DUMMY_NODE_VECTOR0 Vector__XXX;

EV_ evShowIdle: 0 [0|0] "" 0 5 DUMMY_NODE_VECTOR0 Vector__XXX;

EV_ evShowGear: 0 [0|6] "" 0 6 DUMMY_NODE_VECTOR0 Vector__XXX;

EV_ evShowFriction: 1 [0|0] "" 0 7 DUMMY_NODE_VECTOR1  Display;

EV_ evShowEngSpeed: 1 [0|5000] "" 0 8 DUMMY_NODE_VECTOR0 Vector__XXX;

EV_ evPedalPosition: 1 [0|100] "" 0 9 DUMMY_NODE_VECTOR3  EngineControl;

EV_ evKombiTurnIndRight: 0 [0|0] "" 0 10 DUMMY_NODE_VECTOR1 Vector__XXX;

EV_ evKombiTurnIndLeft: 0 [0|0] "" 0 11 DUMMY_NODE_VECTOR1 Vector__XXX;

EV_ evKombiSpeed: 1 [0|260] "" 0 12 DUMMY_NODE_VECTOR3 Vector__XXX;

EV_ evKombiLightning: 0 [0|0] "" 0 13 DUMMY_NODE_VECTOR1 Vector__XXX;

EV_ evKombiLightState: 0 [0|0] "" 0 14 DUMMY_NODE_VECTOR0 Vector__XXX;

EV_ evKombiEngTemp: 1 [-40|210] "" 0 15 DUMMY_NODE_VECTOR0 Vector__XXX;

EV_ evKombiEngSpeed: 1 [0|9000] "" 0 16 DUMMY_NODE_VECTOR0 Vector__XXX;

EV_ evKombiBenzin: 0 [0|1] "" 0 17 DUMMY_NODE_VECTOR0 Vector__XXX;

EV_ evGwSwitchIgnition: 0 [0|0] "" 0 18 DUMMY_NODE_VECTOR1 Vector__XXX;

EV_ evGwStarterState: 0 [0|1] "" 0 19 DUMMY_NODE_VECTOR1 Vector__XXX;

EV_ evGwStarterOn: 0 [0|1] "" 0 20 DUMMY_NODE_VECTOR1 Vector__XXX;

EV_ evGwEngRunningInd: 0 [0|0] "" 0 21 DUMMY_NODE_VECTOR3 Vector__XXX;

EV_ evGearUp: 0 [0|0] "" 0 22 DUMMY_NODE_VECTOR0 Vector__XXX;

EV_ evGearDown: 0 [0|0] "" 0 23 DUMMY_NODE_VECTOR0 Vector__XXX;

EV_ evGear: 0 [0|5] "" 1 24 DUMMY_NODE_VECTOR3  EngineControl,GearBox;

EV_ evFloatDebug3: 1 [0|0] "" 0 25 DUMMY_NODE_VECTOR0 Vector__XXX;

EV_ evFloatDebug2: 1 [0|0] "" 0 26 DUMMY_NODE_VECTOR0 Vector__XXX;

EV_ evFloatDebug1: 1 [0|0] "" 0 27 DUMMY_NODE_VECTOR0 Vector__XXX;

EV_ evDispWarnInd: 0 [0|0] "" 0 28 DUMMY_NODE_VECTOR2 Vector__XXX;

EV_ evDispTurnIndRight: 0 [0|0] "" 0 29 DUMMY_NODE_VECTOR2 Vector__XXX;

EV_ evDispTurnIndLeft: 0 [0|0] "" 0 30 DUMMY_NODE_VECTOR2 Vector__XXX;

EV_ evDispStarter: 0 [0|0] "" 0 31 DUMMY_NODE_VECTOR2 Vector__XXX;

EV_ evDispSpeed: 0 [0|15] "" 0 32 DUMMY_NODE_VECTOR0 Vector__XXX;

EV_ evDispLightOn: 0 [0|0] "" 0 33 DUMMY_NODE_VECTOR2 Vector__XXX;

EV_ evDispLight: 0 [0|0] "" 0 34 DUMMY_NODE_VECTOR2 Vector__XXX;

EV_ evDispIg15r: 0 [0|0] "" 0 35 DUMMY_NODE_VECTOR2 Vector__XXX;

EV_ evDispIg15: 0 [0|0] "" 0 36 DUMMY_NODE_VECTOR2 Vector__XXX;

EV_ evDispFHRstate: 0 [0|0] "" 0 37 DUMMY_NODE_VECTOR2 Vector__XXX;

EV_ evDispFHLstate: 0 [0|0] "" 0 38 DUMMY_NODE_VECTOR2 Vector__XXX;

EV_ evDispEngTemp: 0 [0|3] "" 0 39 DUMMY_NODE_VECTOR0 Vector__XXX;

EV_ evDispEngSpeed: 0 [0|15] "" 0 40 DUMMY_NODE_VECTOR0 Vector__XXX;

EV_ evDispBenzin: 0 [0|3] "" 0 41 DUMMY_NODE_VECTOR0 Vector__XXX;

EV_ evBreakActive: 0 [0|1] "" 0 42 DUMMY_NODE_VECTOR3  EngineControl;

CM_ BO_ 2147544832 "EZS200

Byte    1: KL_15                Klemmenstatus
        2: Signale              Blinkerschaltung/Hupenkontakt
        3: Wischer              Wisch-/Wasch Schalter
        4: Ubatt                Bordnetzspannung

tz[msec]         tw[msec]          sofort/imZyklus
------------------------------------------------------------
100              -                 sofort



";
CM_ EV_ evGwStarterState "Starter state in contrast to push button state";
BA_DEF_ SG_  "SigType" STRING ;
BA_DEF_  "J1939PGN" INT 0 1;
BA_DEF_ BO_  "J1939PGPrio" INT 0 7;
BA_DEF_ BO_  "CycleTime" INT 5 1000;
BA_DEF_DEF_  "SigType" "";
BA_DEF_DEF_  "J1939PGN" 0;
BA_DEF_DEF_  "J1939PGPrio" 6;
BA_DEF_DEF_  "CycleTime" 100;
BA_ "J1939PGN" 1;
BA_ "J1939PGPrio" BO_ 2147483648 3;
BA_ "J1939PGPrio" BO_ 2147483904 3;
BA_ "J1939PGPrio" BO_ 2147548867 7;
BA_ "J1939PGPrio" BO_ 2147548869 7;
BA_ "J1939PGPrio" BO_ 2147548871 7;
BA_ "J1939PGPrio" BO_ 2147545090 3;
BA_ "J1939PGPrio" BO_ 2147548866 7;
BA_ "J1939PGPrio" BO_ 2147545091 3;
BA_ "J1939PGPrio" BO_ 2147545092 3;
BA_ "SigType" SG_ 2147548863 RelSpeedRearAxle_2RightWheel "RANGE";
BA_ "SigType" SG_ 2147548863 RelSpeedRearAxle_2LeftWheel "RANGE";
BA_ "SigType" SG_ 2147548863 RelSpeedRearAxle_1RightWheel "RANGE";
BA_ "SigType" SG_ 2147548863 RelSpeedRearAxle_1LeftWheel "RANGE";
BA_ "SigType" SG_ 2147548863 RelSpeedFrontAxleRightWheel "RANGE";
BA_ "SigType" SG_ 2147548863 RelSpeedFrontAxleLeftWheel "RANGE";
BA_ "SigType" SG_ 2147548863 FrontAxleSpeed "RANGE";
BA_ "SigType" SG_ 2147548927 WaterInFuelIndicator "DISCRETE";
BA_ "SigType" SG_ 2147548906 TrailerWeight "RANGE";
BA_ "SigType" SG_ 2147548906 CargoWeight "RANGE";
BA_ "SigType" SG_ 2147548906 AxleWeight "RANGE";
BA_ "SigType" SG_ 2147548906 AxleLocation "SPECIFIC";
BA_ "SigType" SG_ 2147548915 Longitude "RANGE";
BA_ "SigType" SG_ 2147548915 Latitude "RANGE";
BA_ "SigType" SG_ 2147548903 TotalVehicleHours "RANGE";
BA_ "SigType" SG_ 2147548903 TotalPowerTakeoffHours "RANGE";
BA_ "SigType" SG_ 2147548919 NetBatteryCurrent "RANGE";
BA_ "SigType" SG_ 2147548919 ElectricalPotential "RANGE";
BA_ "SigType" SG_ 2147548919 BatteryPotentialSwitched "RANGE";
BA_ "SigType" SG_ 2147548919 AlternatorPotential "RANGE";
BA_ "SigType" SG_ 2147548919 AlternatorCurrent "RANGE";
BA_ "SigType" SG_ 2147548896 TripDistance "RANGE";
BA_ "SigType" SG_ 2147548896 TotalVehicleDistance "RANGE";
BA_ "SigType" SG_ 2147548904 Pitch "RANGE";
BA_ "SigType" SG_ 2147548904 Navigation_BasedVehicleSpeed "RANGE";
BA_ "SigType" SG_ 2147548904 CompassBearing "RANGE";
BA_ "SigType" SG_ 2147548904 Altitude "RANGE";
BA_ "SigType" SG_ 2147548893 TurboSpeed "RANGE";
BA_ "SigType" SG_ 2147548893 TurboOilPressure "RANGE";
BA_ "SigType" SG_ 2147548920 TransmissionOilTemperature "RANGE";
BA_ "SigType" SG_ 2147548920 TransmissionOilPressure "RANGE";
BA_ "SigType" SG_ 2147548920 TransmissionOilLevel "RANGE";
BA_ "SigType" SG_ 2147548920 TransmissionFilterDiffPressure "RANGE";
BA_ "SigType" SG_ 2147548920 ClutchPressure "RANGE";
BA_ "SigType" SG_ 2147548898 NumberOfReverseGearRatios "RANGE";
BA_ "SigType" SG_ 2147548898 NumberOfForwardGearRatios "RANGE";
BA_ "SigType" SG_ 2147548898 MiddleReverseGearRatio "RANGE";
BA_ "SigType" SG_ 2147548898 MiddleForwardGearRatio "RANGE";
BA_ "SigType" SG_ 2147548898 LowestReverseGearRatio "RANGE";
BA_ "SigType" SG_ 2147548898 LowestForwardGearRatio "RANGE";
BA_ "SigType" SG_ 2147548898 HighestReverseGearRatio "RANGE";
BA_ "SigType" SG_ 2147548898 HighestForwardGearRatio "RANGE";
BA_ "SigType" SG_ 2147548916 TireTemperature "RANGE";
BA_ "SigType" SG_ 2147548916 TirePressure "RANGE";
BA_ "SigType" SG_ 2147548916 Location "SPECIFIC";
BA_ "SigType" SG_ 2147548902 Year "RANGE";
BA_ "SigType" SG_ 2147548902 Seconds "RANGE";
BA_ "SigType" SG_ 2147548902 Month "RANGE";
BA_ "SigType" SG_ 2147548902 Minutes "RANGE";
BA_ "SigType" SG_ 2147548902 Hours "RANGE";
BA_ "SigType" SG_ 2147548902 Day "RANGE";
BA_ "SigType" SG_ 2147483648 RqstedTorque_TorqueLimit "RANGE";
BA_ "SigType" SG_ 2147483648 RqstedSpeed_SpeedLimit "RANGE";
BA_ "SigType" SG_ 2147483648 RqstedSpeedCtrlConditions "CONTROL";
BA_ "SigType" SG_ 2147483648 OverrideCtrlModes "CONTROL";
BA_ "SigType" SG_ 2147483648 OverrideCtrlModePriority "CONTROL";
BA_ "SigType" SG_ 2147543808 SeqNumber "SPECIFIC";
BA_ "SigType" SG_ 2147543808 Byte7 "SPECIFIC";
BA_ "SigType" SG_ 2147543808 Byte6 "SPECIFIC";
BA_ "SigType" SG_ 2147543808 Byte5 "SPECIFIC";
BA_ "SigType" SG_ 2147543808 Byte4 "SPECIFIC";
BA_ "SigType" SG_ 2147543808 Byte3 "SPECIFIC";
BA_ "SigType" SG_ 2147543808 Byte2 "SPECIFIC";
BA_ "SigType" SG_ 2147543808 Byte1 "SPECIFIC";
BA_ "SigType" SG_ 2147544064 SendPackets "SPECIFIC";
BA_ "SigType" SG_ 2147544064 RtsNoPackets "SPECIFIC";
BA_ "SigType" SG_ 2147544064 RtsMsgSize "SPECIFIC";
BA_ "SigType" SG_ 2147544064 PGNumber "SPECIFIC";
BA_ "SigType" SG_ 2147544064 NextPacket "SPECIFIC";
BA_ "SigType" SG_ 2147544064 ControlByte "SPECIFIC";
BA_ "SigType" SG_ 2147544064 BamNoPackets "SPECIFIC";
BA_ "SigType" SG_ 2147544064 BamMsgSize "SPECIFIC";
BA_ "SigType" SG_ 2147544064 AckNoPackets "SPECIFIC";
BA_ "SigType" SG_ 2147544064 AckMsgSize "SPECIFIC";
BA_ "SigType" SG_ 2147483904 TorqueConverterLockDisbleRqst "CONTROL";
BA_ "SigType" SG_ 2147483904 RqstedPercentClutchSlip "RANGE";
BA_ "SigType" SG_ 2147483904 RqstedGear "RANGE";
BA_ "SigType" SG_ 2147483904 GearShiftInhibitRqst "CONTROL";
BA_ "SigType" SG_ 2147483904 DisengageDrivelineRqst "CONTROL";
BA_ "SigType" SG_ 2147483904 DisengageDiff_Lock2CentralRear "CONTROL";
BA_ "SigType" SG_ 2147483904 DisengageDiff_Lock2CentralFront "CONTROL";
BA_ "SigType" SG_ 2147483904 DisengageDiff_Lock2Central "CONTROL";
BA_ "SigType" SG_ 2147483904 DisengageDiff_Lock1RearAxle2 "CONTROL";
BA_ "SigType" SG_ 2147483904 DisengageDiff_Lock1RearAxle1 "CONTROL";
BA_ "SigType" SG_ 2147483904 DisengageDiff_Lock1FrontAxle2 "CONTROL";
BA_ "SigType" SG_ 2147483904 DisengageDiff_Lock1FrontAxle1 "CONTROL";
BA_ "SigType" SG_ 2147548864 ServiceDistance "RANGE";
BA_ "SigType" SG_ 2147548864 ServiceDelay_OpTimeBased "RANGE";
BA_ "SigType" SG_ 2147548864 ServiceDelay_CalendarTimeBased "RANGE";
BA_ "SigType" SG_ 2147548864 ServiceComponentId_3 "SPECIFIC";
BA_ "SigType" SG_ 2147548864 ServiceComponentId_2 "SPECIFIC";
BA_ "SigType" SG_ 2147548864 ServiceComponentId_1 "SPECIFIC";
BA_ "SigType" SG_ 2147548923 HydraulicRetarderPressure "RANGE";
BA_ "SigType" SG_ 2147548923 HydraulicRetarderOilTemp "RANGE";
BA_ "SigType" SG_ 2147548897 RetarderType "SPECIFIC";
BA_ "SigType" SG_ 2147548897 RetarderSpeedAtPt4 "RANGE";
BA_ "SigType" SG_ 2147548897 RetarderSpeedAtPt3 "RANGE";
BA_ "SigType" SG_ 2147548897 RetarderSpeedAtPeakTorquePt5 "RANGE";
BA_ "SigType" SG_ 2147548897 RetarderSpeedAtIdlePt1 "RANGE";
BA_ "SigType" SG_ 2147548897 RetarderLocation "SPECIFIC";
BA_ "SigType" SG_ 2147548897 RetarderCtrlMethod "RANGE";
BA_ "SigType" SG_ 2147548897 ReferenceRetarderTorque "RANGE";
BA_ "SigType" SG_ 2147548897 PercentTorqueAtPt4 "RANGE";
BA_ "SigType" SG_ 2147548897 PercentTorqueAtPt3 "RANGE";
BA_ "SigType" SG_ 2147548897 PercentTorqueAtPeakTorquePt5 "RANGE";
BA_ "SigType" SG_ 2147548897 PercentTorqueAtMaxSpeedPt2 "RANGE";
BA_ "SigType" SG_ 2147548897 PercentTorqueAtIdlePt1 "RANGE";
BA_ "SigType" SG_ 2147548897 MaximumRetarderSpeedPt2 "RANGE";
BA_ "SigType" SG_ 2147543552 RqstedPGN "SPECIFIC";
BA_ "SigType" SG_ 2147548931 ManufacturerSpecific8 "SPECIFIC";
BA_ "SigType" SG_ 2147548931 ManufacturerSpecific7 "SPECIFIC";
BA_ "SigType" SG_ 2147548931 ManufacturerSpecific6 "SPECIFIC";
BA_ "SigType" SG_ 2147548931 ManufacturerSpecific5 "SPECIFIC";
BA_ "SigType" SG_ 2147548931 ManufacturerSpecific4 "SPECIFIC";
BA_ "SigType" SG_ 2147548931 ManufacturerSpecific3 "SPECIFIC";
BA_ "SigType" SG_ 2147548931 ManufacturerSpecific2 "SPECIFIC";
BA_ "SigType" SG_ 2147548931 ManufacturerSpecific1 "SPECIFIC";
BA_ "SigType" SG_ 2147548930 ManufacturerSpecific8 "SPECIFIC";
BA_ "SigType" SG_ 2147548930 ManufacturerSpecific7 "SPECIFIC";
BA_ "SigType" SG_ 2147548930 ManufacturerSpecific6 "SPECIFIC";
BA_ "SigType" SG_ 2147548930 ManufacturerSpecific5 "SPECIFIC";
BA_ "SigType" SG_ 2147548930 ManufacturerSpecific4 "SPECIFIC";
BA_ "SigType" SG_ 2147548930 ManufacturerSpecific3 "SPECIFIC";
BA_ "SigType" SG_ 2147548930 ManufacturerSpecific2 "SPECIFIC";
BA_ "SigType" SG_ 2147548930 ManufacturerSpecific1 "SPECIFIC";
BA_ "SigType" SG_ 2147548929 ManufacturerSpecific8 "SPECIFIC";
BA_ "SigType" SG_ 2147548929 ManufacturerSpecific7 "SPECIFIC";
BA_ "SigType" SG_ 2147548929 ManufacturerSpecific6 "SPECIFIC";
BA_ "SigType" SG_ 2147548929 ManufacturerSpecific5 "SPECIFIC";
BA_ "SigType" SG_ 2147548929 ManufacturerSpecific4 "SPECIFIC";
BA_ "SigType" SG_ 2147548929 ManufacturerSpecific3 "SPECIFIC";
BA_ "SigType" SG_ 2147548929 ManufacturerSpecific2 "SPECIFIC";
BA_ "SigType" SG_ 2147548929 ManufacturerSpecific1 "SPECIFIC";
BA_ "SigType" SG_ 2147548928 ManufacturerSpecific8 "SPECIFIC";
BA_ "SigType" SG_ 2147548928 ManufacturerSpecific7 "SPECIFIC";
BA_ "SigType" SG_ 2147548928 ManufacturerSpecific6 "SPECIFIC";
BA_ "SigType" SG_ 2147548928 ManufacturerSpecific5 "SPECIFIC";
BA_ "SigType" SG_ 2147548928 ManufacturerSpecific4 "SPECIFIC";
BA_ "SigType" SG_ 2147548928 ManufacturerSpecific3 "SPECIFIC";
BA_ "SigType" SG_ 2147548928 ManufacturerSpecific2 "SPECIFIC";
BA_ "SigType" SG_ 2147548928 ManufacturerSpecific1 "SPECIFIC";
BA_ "SigType" SG_ 2147548912 PowerTakeoffSpeed "RANGE";
BA_ "SigType" SG_ 2147548912 PowerTakeoffSetSpeed "RANGE";
BA_ "SigType" SG_ 2147548912 PowerTakeoffOilTemperature "RANGE";
BA_ "SigType" SG_ 2147548918 ParticulateTrapInletPressure "RANGE";
BA_ "SigType" SG_ 2147548918 IntakeManifoldTemperature "RANGE";
BA_ "SigType" SG_ 2147548918 ExhaustGasTemperature "RANGE";
BA_ "SigType" SG_ 2147548918 CoolantFilterDiffPressure "RANGE";
BA_ "SigType" SG_ 2147548918 BoostPressure "RANGE";
BA_ "SigType" SG_ 2147548918 AirInletPressure "RANGE";
BA_ "SigType" SG_ 2147548918 AirFilterDifferentialPressure "RANGE";
BA_ "SigType" SG_ 2147548900 IdleShutdownTimerState "CONTROL";
BA_ "SigType" SG_ 2147548900 IdleShutdownTimerOverride "CONTROL";
BA_ "SigType" SG_ 2147548900 IdleShutdownTimerFunction "DISCRETE";
BA_ "SigType" SG_ 2147548900 EngineHasShutdownBySystem "CONTROL";
BA_ "SigType" SG_ 2147548900 DriverAlertMode "CONTROL";
BA_ "SigType" SG_ 2147548892 TotalIdleHours "RANGE";
BA_ "SigType" SG_ 2147548892 TotalIdleFuelUsed "RANGE";
BA_ "SigType" SG_ 2147548865 HighResolTripDistance "RANGE";
BA_ "SigType" SG_ 2147548865 HighResolTotalVehicleDistance "RANGE";
BA_ "SigType" SG_ 2147548914 InstantaneousFuelEconomy "RANGE";
BA_ "SigType" SG_ 2147548914 FuelRate "RANGE";
BA_ "SigType" SG_ 2147548914 AverageFuelEconomy "RANGE";
BA_ "SigType" SG_ 2147548905 TripFuel "RANGE";
BA_ "SigType" SG_ 2147548905 TotalFuelUsed "RANGE";
BA_ "SigType" SG_ 2147548910 TurboOilTemperature "RANGE";
BA_ "SigType" SG_ 2147548910 FuelTemperature "RANGE";
BA_ "SigType" SG_ 2147548910 EngineOilTemperature "RANGE";
BA_ "SigType" SG_ 2147548910 EngineIntercoolerTemperature "RANGE";
BA_ "SigType" SG_ 2147548910 EngineCoolantTemperature "RANGE";
BA_ "SigType" SG_ 2147548901 TotalEngineRevolutions "RANGE";
BA_ "SigType" SG_ 2147548901 TotalEngineHours "RANGE";
BA_ "SigType" SG_ 2147548891 InjectorMeteringRailPressure "RANGE";
BA_ "SigType" SG_ 2147548891 InjectionCtrlPressure "RANGE";
BA_ "SigType" SG_ 2147548911 FuelDeliveryPressure "RANGE";
BA_ "SigType" SG_ 2147548911 EngineOilPressure "RANGE";
BA_ "SigType" SG_ 2147548911 EngineOilLevel "RANGE";
BA_ "SigType" SG_ 2147548911 CrankcasePressure "RANGE";
BA_ "SigType" SG_ 2147548911 CoolantPressure "RANGE";
BA_ "SigType" SG_ 2147548911 CoolantLevel "RANGE";
BA_ "SigType" SG_ 2147548899 RqstedTorqueCtrlRangeUpperLimit "RANGE";
BA_ "SigType" SG_ 2147548899 RqstedTorqueCtrlRangeLowerLimit "RANGE";
BA_ "SigType" SG_ 2147548899 RqstedSpeedCtrlRangeUpperLimit "RANGE";
BA_ "SigType" SG_ 2147548899 RqstedSpeedCtrlRangeLowerLimit "RANGE";
BA_ "SigType" SG_ 2147548899 ReferenceEngineTorque "RANGE";
BA_ "SigType" SG_ 2147548899 PercentTorqueAtPt5 "RANGE";
BA_ "SigType" SG_ 2147548899 PercentTorqueAtPt4 "RANGE";
BA_ "SigType" SG_ 2147548899 PercentTorqueAtPt3 "RANGE";
BA_ "SigType" SG_ 2147548899 PercentTorqueAtPt2 "RANGE";
BA_ "SigType" SG_ 2147548899 PercentTorqueAtIdlePt1 "RANGE";
BA_ "SigType" SG_ 2147548899 MaxMomentEngineOvrwrtTimeLimit "RANGE";
BA_ "SigType" SG_ 2147548899 MaxMomentEngineOvrwrtSpeedPt7 "RANGE";
BA_ "SigType" SG_ 2147548899 GainOfEndspeedGovernor "RANGE";
BA_ "SigType" SG_ 2147548899 EngineSpeedAtPt5 "RANGE";
BA_ "SigType" SG_ 2147548899 EngineSpeedAtPt4 "RANGE";
BA_ "SigType" SG_ 2147548899 EngineSpeedAtPt3 "RANGE";
BA_ "SigType" SG_ 2147548899 EngineSpeedAtPt2 "RANGE";
BA_ "SigType" SG_ 2147548899 EngineSpeedAtIdlePt1 "RANGE";
BA_ "SigType" SG_ 2147548899 EngineSpeedAtHighIdlePt6 "RANGE";
BA_ "SigType" SG_ 2147548867 ReverseSwitch "CONTROL";
BA_ "SigType" SG_ 2147548867 NeutralSwitch "CONTROL";
BA_ "SigType" SG_ 2147548867 LowRangeSense "CONTROL";
BA_ "SigType" SG_ 2147548867 HighRangeSense "CONTROL";
BA_ "SigType" SG_ 2147548867 ForwardSwitch "CONTROL";
BA_ "SigType" SG_ 2147548869 TransmissionSynchroClutchVal "RANGE";
BA_ "SigType" SG_ 2147548869 TransmissionSynchroBrakeVal "RANGE";
BA_ "SigType" SG_ 2147548871 SplitterIndirectActuator "CONTROL";
BA_ "SigType" SG_ 2147548871 SplitterDirectActuator "CONTROL";
BA_ "SigType" SG_ 2147548871 ShiftFingerRailPosition "RANGE";
BA_ "SigType" SG_ 2147548871 ShiftFingerGearPosition "RANGE";
BA_ "SigType" SG_ 2147548871 RangeLowActuator "CONTROL";
BA_ "SigType" SG_ 2147548871 RangeHighActuator "CONTROL";
BA_ "SigType" SG_ 2147548871 RailActuator_2 "CONTROL";
BA_ "SigType" SG_ 2147548871 RailActuator_1 "CONTROL";
BA_ "SigType" SG_ 2147548871 NeutralIndicator "CONTROL";
BA_ "SigType" SG_ 2147548871 LockupClutchActuator "CONTROL";
BA_ "SigType" SG_ 2147548871 InertiaBrakeActuator "CONTROL";
BA_ "SigType" SG_ 2147548871 GearActuator_2 "CONTROL";
BA_ "SigType" SG_ 2147548871 GearActuator_1 "CONTROL";
BA_ "SigType" SG_ 2147548871 EngagementIndicator "CONTROL";
BA_ "SigType" SG_ 2147548871 DefuelActuator "CONTROL";
BA_ "SigType" SG_ 2147548871 ClutchActuator "CONTROL";
BA_ "SigType" SG_ 2147548871 CenterRailIndicator "CONTROL";
BA_ "SigType" SG_ 2147545093 TransmissionRqstedRange "ASCII";
BA_ "SigType" SG_ 2147545093 TransmissionCurrentRange "ASCII";
BA_ "SigType" SG_ 2147545093 SelectedGear "RANGE";
BA_ "SigType" SG_ 2147545093 CurrentGear "RANGE";
BA_ "SigType" SG_ 2147545093 ActualGearRatio "RANGE";
BA_ "SigType" SG_ 2147545090 TorqueConverterLockupEngaged "CONTROL";
BA_ "SigType" SG_ 2147545090 ShiftInProcess "DISCRETE";
BA_ "SigType" SG_ 2147545090 ProgressiveShiftDisable "CONTROL";
BA_ "SigType" SG_ 2147545090 PercentClutchSlip "RANGE";
BA_ "SigType" SG_ 2147545090 OutputShaftSpeed "RANGE";
BA_ "SigType" SG_ 2147545090 MomentaryEngineOverspeedEnable "CONTROL";
BA_ "SigType" SG_ 2147545090 InputShaftSpeed "RANGE";
BA_ "SigType" SG_ 2147545090 DrivelineEngaged "DISCRETE";
BA_ "SigType" SG_ 2147548866 TransmissionOutputRetarder "CONTROL";
BA_ "SigType" SG_ 2147545088 RetarderEnableShiftAssistSwtch "DISCRETE";
BA_ "SigType" SG_ 2147545088 RetarderEnableBrakeAssistSwtch "DISCRETE";
BA_ "SigType" SG_ 2147545088 EngineRetarderTorqueMode "SPECIFIC";
BA_ "SigType" SG_ 2147545088 ActualRetarderPercentTorque "RANGE";
BA_ "SigType" SG_ 2147548862 RatedEngineSpeed "RANGE";
BA_ "SigType" SG_ 2147548862 RatedEnginePower "RANGE";
BA_ "SigType" SG_ 2147548895 NominalFriction_PercentTorque "RANGE";
BA_ "SigType" SG_ 2147548895 EngineOperateSpeedAsymAdjstmnt "RANGE";
BA_ "SigType" SG_ 2147548895 EngineDesiredOperatingSpeed "RANGE";
BA_ "SigType" SG_ 2147545091 PercentLoadAtCurrentSpeed "RANGE";
BA_ "SigType" SG_ 2147545091 AcceleratorPedalPosition "RANGE";
BA_ "SigType" SG_ 2147545091 APLowIdleSwitch "DISCRETE";
BA_ "SigType" SG_ 2147545091 APKickdownSwitch "DISCRETE";
BA_ "SigType" SG_ 2147545092 EngineSpeed "RANGE";
BA_ "SigType" SG_ 2147545092 EngineRetarderTorqueMode "SPECIFIC";
BA_ "SigType" SG_ 2147545092 DriversDemandEngine_PercTorque "RANGE";
BA_ "SigType" SG_ 2147545092 ActualEngine_PercTorque "RANGE";
BA_ "SigType" SG_ 2147545089 BrakePedalPosition "RANGE";
BA_ "SigType" SG_ 2147545089 ASROffroadSwitch "DISCRETE";
BA_ "SigType" SG_ 2147545089 ASRHillHolderSwitch "DISCRETE";
BA_ "SigType" SG_ 2147545089 ASREngineCtrlActive "CONTROL";
BA_ "SigType" SG_ 2147545089 ASRBrakeCtrlActive "CONTROL";
BA_ "SigType" SG_ 2147545089 ABSOffroadSwitch "DISCRETE";
BA_ "SigType" SG_ 2147545089 ABSActive "CONTROL";
BA_ "SigType" SG_ 2147545094 Location "SPECIFIC";
BA_ "SigType" SG_ 2147545094 DifferentialLockRearAxle2 "CONTROL";
BA_ "SigType" SG_ 2147545094 DifferentialLockRearAxle1 "CONTROL";
BA_ "SigType" SG_ 2147545094 DifferentialLockFrontAxle2 "CONTROL";
BA_ "SigType" SG_ 2147545094 DifferentialLockFrontAxle1 "CONTROL";
BA_ "SigType" SG_ 2147545094 DifferentialCentralRear "CONTROL";
BA_ "SigType" SG_ 2147545094 DifferentialCentralFront "CONTROL";
BA_ "SigType" SG_ 2147545094 DifferentialCentral "CONTROL";
BA_ "SigType" SG_ 2147548924 WasherFluidLevel "RANGE";
BA_ "SigType" SG_ 2147548924 FuelLevel "RANGE";
BA_ "SigType" SG_ 2147548924 FuelFilterDiffPressure "RANGE";
BA_ "SigType" SG_ 2147548924 EngineOilFilterDiffPressure "RANGE";
BA_ "SigType" SG_ 2147548924 CargoAmbientTemperature "RANGE";
BA_ "SigType" SG_ 2147548909 MaximumVehicleSpeedLimit "RANGE";
BA_ "SigType" SG_ 2147548909 CruiseCtrlLowSetLimitSpeed "RANGE";
BA_ "SigType" SG_ 2147548909 CruiseCtrlHighSetLimitSpeed "RANGE";
BA_ "SigType" SG_ 2147548913 Wheel_BasedVehicleSpeed "RANGE";
BA_ "SigType" SG_ 2147548913 TwoSpeedAxleSwitch "DISCRETE";
BA_ "SigType" SG_ 2147548913 ParkingBrakeSwitch "DISCRETE";
BA_ "SigType" SG_ 2147548913 IdleIncrementSwitch "DISCRETE";
BA_ "SigType" SG_ 2147548913 IdleDecrementSwitch "DISCRETE";
BA_ "SigType" SG_ 2147548913 EngineTestModeSwitch "DISCRETE";
BA_ "SigType" SG_ 2147548913 CruiseCtrlState "SPECIFIC";
BA_ "SigType" SG_ 2147548913 CruiseCtrlSetSwitch "DISCRETE";
BA_ "SigType" SG_ 2147548913 CruiseCtrlSetSpeed "RANGE";
BA_ "SigType" SG_ 2147548913 CruiseCtrlResumeSwitch "DISCRETE";
BA_ "SigType" SG_ 2147548913 CruiseCtrlEnableSwitch "DISCRETE";
BA_ "SigType" SG_ 2147548913 CruiseCtrlCoastSwitch "DISCRETE";
BA_ "SigType" SG_ 2147548913 CruiseCtrlActive "DISCRETE";
BA_ "SigType" SG_ 2147548913 CruiseCtrlAccelerateSwitch "DISCRETE";
BA_ "SigType" SG_ 2147548913 ClutchSwitch "DISCRETE";
BA_ "SigType" SG_ 2147548913 BrakeSwitch "DISCRETE";
BA_ "SigType" SG_ 2147548922 ParkingBrakeActuator "DISCRETE";
BA_ "SigType" SG_ 2147548922 BrakeSecondaryPressure "RANGE";
BA_ "SigType" SG_ 2147548922 BrakePrimaryPressure "RANGE";
BA_ "SigType" SG_ 2147548922 BrakeApplicationPressure "RANGE";
BA_ "SigType" SG_ 2147548921 SteeringAxleTemperature "RANGE";
BA_ "SigType" SG_ 2147548921 DriveAxleTemperature "RANGE";
BA_ "SigType" SG_ 2147548921 DriveAxleLocation "SPECIFIC";
BA_ "SigType" SG_ 2147548921 DriveAxleLiftAirPressure "RANGE";
BA_ "SigType" SG_ 2147548926 AuxiliaryPumpPressure "RANGE";
BA_ "SigType" SG_ 2147548889 I_OChannel_9 "DISCRETE";
BA_ "SigType" SG_ 2147548889 I_OChannel_8 "DISCRETE";
BA_ "SigType" SG_ 2147548889 I_OChannel_7 "DISCRETE";
BA_ "SigType" SG_ 2147548889 I_OChannel_6 "DISCRETE";
BA_ "SigType" SG_ 2147548889 I_OChannel_5 "DISCRETE";
BA_ "SigType" SG_ 2147548889 I_OChannel_4 "DISCRETE";
BA_ "SigType" SG_ 2147548889 I_OChannel_3 "DISCRETE";
BA_ "SigType" SG_ 2147548889 I_OChannel_2 "DISCRETE";
BA_ "SigType" SG_ 2147548889 I_OChannel_16 "DISCRETE";
BA_ "SigType" SG_ 2147548889 I_OChannel_15 "DISCRETE";
BA_ "SigType" SG_ 2147548889 I_OChannel_14 "DISCRETE";
BA_ "SigType" SG_ 2147548889 I_OChannel_13 "DISCRETE";
BA_ "SigType" SG_ 2147548889 I_OChannel_12 "DISCRETE";
BA_ "SigType" SG_ 2147548889 I_OChannel_11 "DISCRETE";
BA_ "SigType" SG_ 2147548889 I_OChannel_10 "DISCRETE";
BA_ "SigType" SG_ 2147548889 I_OChannel_1 "DISCRETE";
BA_ "SigType" SG_ 2147548917 RoadSurfaceTemperature "RANGE";
BA_ "SigType" SG_ 2147548917 CabInteriorTemperature "RANGE";
BA_ "SigType" SG_ 2147548917 BarometricPressure "RANGE";
BA_ "SigType" SG_ 2147548917 AmbientAirTemperature "RANGE";
BA_ "SigType" SG_ 2147548917 AirInletTemperature "RANGE";
BA_ "SigType" SG_ 2147548885 AlternatorSpeed "RANGE";
BA_ "SigType" SG_ 2147548925 GasSupplyPressure "RANGE";
BA_ "SigType" SG_ 2147548925 BlowerBypassValvePosition "RANGE";
BA_ "SigType" SG_ 2147548894 AirStartPressure "RANGE";
BA_ "SigType" SG_ 2147543040 PGN "SPECIFIC";
BA_ "SigType" SG_ 2147543040 CtrlByte "SPECIFIC";
VAL_ 2147548927 WaterInFuelIndicator 3 "NotAvailable" 2 "Error" 1 "Yes" 0 "No" ;
VAL_ 2147548906 AxleLocation 255 "NotAvailable" ;
VAL_ 2147548916 Location 255 "NotAvailable" ;
VAL_ 2147483648 RqstedSpeedCtrlConditions 3 "SODrvLnEngLockup2" 2 "SODrvLnEngLockup1" 1 "SODrvLnDisEngNonLockupCond" 0 "TODrvLnDisEngNonLockupCond" ;
VAL_ 2147483648 OverrideCtrlModes 3 "Speed_TorqueLimitControl" 2 "TorqueControl" 1 "SpeedControl" 0 "OverrideDisabled" ;
VAL_ 2147483648 OverrideCtrlModePriority 3 "NoAction" 2 "Reserved" 1 "Enable" 0 "Highest" ;
VAL_ 2147544064 PGNumber 255 "NotAvailable" ;
VAL_ 2147544064 ControlByte 16 "RTS" 17 "CTS" 19 "EoMACK" 255 "Abort" 32 "BAM" ;
VAL_ 2147483904 TorqueConverterLockDisbleRqst 3 "NoAction" 2 "Reserved" 1 "Disable" 0 "Allow" ;
VAL_ 2147483904 RqstedGear 251 "Park" 0 "Neutral" ;
VAL_ 2147483904 GearShiftInhibitRqst 3 "NoAction" 2 "Reserved" 1 "Inhibited" 0 "Allow" ;
VAL_ 2147483904 DisengageDrivelineRqst 3 "NoAction" 2 "Reserved" 1 "Disengage" 0 "Allow" ;
VAL_ 2147483904 DisengageDiff_Lock2CentralRear 3 "NoAction" 2 "Reserved" 1 "Disengage" 0 "Engage" ;
VAL_ 2147483904 DisengageDiff_Lock2CentralFront 3 "NoAction" 2 "Reserved" 1 "Disengage" 0 "Engage" ;
VAL_ 2147483904 DisengageDiff_Lock2Central 3 "NoAction" 2 "Reserved" 1 "Disengage" 0 "Engage" ;
VAL_ 2147483904 DisengageDiff_Lock1RearAxle2 3 "NoAction" 2 "Reserved" 1 "Disengage" 0 "Engage" ;
VAL_ 2147483904 DisengageDiff_Lock1RearAxle1 3 "NoAction" 2 "Reserved" 1 "Disengage" 0 "Engage" ;
VAL_ 2147483904 DisengageDiff_Lock1FrontAxle2 3 "NoAction" 2 "Reserved" 1 "Disengage" 0 "Engage" ;
VAL_ 2147483904 DisengageDiff_Lock1FrontAxle1 3 "NoAction" 2 "Reserved" 1 "Disengage" 0 "Engage" ;
VAL_ 2147548864 ServiceComponentId_3 5 "ClutchLining" 4 "BrakeLiningRightRearAxle" 255 "NotAvailable" 2 "BrakeLiningRightFrontAxle" 18 "In_BetweenCheck" 17 "BrakeSystemSpecialCheck" 16 "RegulatedGeneralCheckForEntireVe" 1 "BrakeLiningLeftFrontAxle" 0 "ServiceCheckForEntireVehicle" ;
VAL_ 2147548864 ServiceComponentId_2 5 "ClutchLining" 4 "BrakeLiningRightRearAxle" 255 "NotAvailable" 2 "BrakeLiningRightFrontAxle" 18 "In_BetweenCheck" 17 "BrakeSystemSpecialCheck" 16 "RegulatedGeneralCheckForEntireVe" 1 "BrakeLiningLeftFrontAxle" 0 "ServiceCheckForEntireVehicle" ;
VAL_ 2147548864 ServiceComponentId_1 5 "ClutchLining" 4 "BrakeLiningRightRearAxle" 255 "NotAvailable" 2 "BrakeLiningRightFrontAxle" 18 "In_BetweenCheck" 17 "BrakeSystemSpecialCheck" 16 "RegulatedGeneralCheckForEntireVe" 1 "BrakeLiningLeftFrontAxle" 0 "ServiceCheckForEntireVehicle" ;
VAL_ 2147548897 RetarderType 4 "Exhaust" 3 "CopressionRelease" 2 "CooledFriction" 15 "NotAvailable" 14 "Other" 1 "Hydraulic" 0 "Electric_Magnetic" ;
VAL_ 2147548897 RetarderLocation 3 "Transmission" 2 "TransmissionInput" 1 "EngineExhaust" 0 "EngineCompression" ;
VAL_ 2147543552 RqstedPGN 255 "NotAvailable" ;
VAL_ 2147548931 ManufacturerSpecific8 255 "NotAvailable" ;
VAL_ 2147548931 ManufacturerSpecific7 255 "NotAvailable" ;
VAL_ 2147548931 ManufacturerSpecific6 255 "NotAvailable" ;
VAL_ 2147548931 ManufacturerSpecific5 255 "NotAvailable" ;
VAL_ 2147548931 ManufacturerSpecific4 255 "NotAvailable" ;
VAL_ 2147548931 ManufacturerSpecific3 255 "NotAvailable" ;
VAL_ 2147548931 ManufacturerSpecific2 255 "NotAvailable" ;
VAL_ 2147548931 ManufacturerSpecific1 255 "NotAvailable" ;
VAL_ 2147548930 ManufacturerSpecific8 255 "NotAvailable" ;
VAL_ 2147548930 ManufacturerSpecific7 255 "NotAvailable" ;
VAL_ 2147548930 ManufacturerSpecific6 255 "NotAvailable" ;
VAL_ 2147548930 ManufacturerSpecific5 255 "NotAvailable" ;
VAL_ 2147548930 ManufacturerSpecific4 255 "NotAvailable" ;
VAL_ 2147548930 ManufacturerSpecific3 255 "NotAvailable" ;
VAL_ 2147548930 ManufacturerSpecific2 255 "NotAvailable" ;
VAL_ 2147548930 ManufacturerSpecific1 255 "NotAvailable" ;
VAL_ 2147548929 ManufacturerSpecific8 255 "NotAvailable" ;
VAL_ 2147548929 ManufacturerSpecific7 255 "NotAvailable" ;
VAL_ 2147548929 ManufacturerSpecific6 255 "NotAvailable" ;
VAL_ 2147548929 ManufacturerSpecific5 255 "NotAvailable" ;
VAL_ 2147548929 ManufacturerSpecific4 255 "NotAvailable" ;
VAL_ 2147548929 ManufacturerSpecific3 255 "NotAvailable" ;
VAL_ 2147548929 ManufacturerSpecific2 255 "NotAvailable" ;
VAL_ 2147548929 ManufacturerSpecific1 255 "NotAvailable" ;
VAL_ 2147548928 ManufacturerSpecific8 255 "NotAvailable" ;
VAL_ 2147548928 ManufacturerSpecific7 255 "NotAvailable" ;
VAL_ 2147548928 ManufacturerSpecific6 255 "NotAvailable" ;
VAL_ 2147548928 ManufacturerSpecific5 255 "NotAvailable" ;
VAL_ 2147548928 ManufacturerSpecific4 255 "NotAvailable" ;
VAL_ 2147548928 ManufacturerSpecific3 255 "NotAvailable" ;
VAL_ 2147548928 ManufacturerSpecific2 255 "NotAvailable" ;
VAL_ 2147548928 ManufacturerSpecific1 255 "NotAvailable" ;
VAL_ 2147548900 IdleShutdownTimerState 3 "NoAction" 2 "Reserved" 1 "Active" 0 "Inactive" ;
VAL_ 2147548900 IdleShutdownTimerOverride 3 "NoAction" 2 "Reserved" 1 "Active" 0 "Inactive" ;
VAL_ 2147548900 IdleShutdownTimerFunction 3 "NotAvailable" 2 "Error" 1 "Enabled" 0 "Disabled" ;
VAL_ 2147548900 EngineHasShutdownBySystem 3 "NoAction" 2 "Reserved" 1 "Yes" 0 "No" ;
VAL_ 2147548900 DriverAlertMode 3 "NoAction" 2 "Reserved" 1 "Active" 0 "Inactive" ;
VAL_ 2147548867 ReverseSwitch 3 "NoAction" 2 "Reserved" 1 "On" 0 "Off" ;
VAL_ 2147548867 NeutralSwitch 3 "NoAction" 2 "Reserved" 1 "On" 0 "Off" ;
VAL_ 2147548867 LowRangeSense 3 "NoAction" 2 "Reserved" 1 "On" 0 "Off" ;
VAL_ 2147548867 HighRangeSense 3 "NoAction" 2 "Reserved" 1 "On" 0 "Off" ;
VAL_ 2147548867 ForwardSwitch 3 "NoAction" 2 "Reserved" 1 "On" 0 "Off" ;
VAL_ 2147548871 SplitterIndirectActuator 3 "NoAction" 2 "Reserved" 1 "On" 0 "Off" ;
VAL_ 2147548871 SplitterDirectActuator 3 "NoAction" 2 "Reserved" 1 "On" 0 "Off" ;
VAL_ 2147548871 RangeLowActuator 3 "NoAction" 2 "Reserved" 1 "On" 0 "Off" ;
VAL_ 2147548871 RangeHighActuator 3 "NoAction" 2 "Reserved" 1 "On" 0 "Off" ;
VAL_ 2147548871 RailActuator_2 3 "NoAction" 2 "Reserved" 1 "On" 0 "Off" ;
VAL_ 2147548871 RailActuator_1 3 "NoAction" 2 "Reserved" 1 "On" 0 "Off" ;
VAL_ 2147548871 NeutralIndicator 3 "NoAction" 2 "Reserved" 1 "On" 0 "Off" ;
VAL_ 2147548871 LockupClutchActuator 3 "NoAction" 2 "Reserved" 1 "On" 0 "Off" ;
VAL_ 2147548871 InertiaBrakeActuator 3 "NoAction" 2 "Reserved" 1 "On" 0 "Off" ;
VAL_ 2147548871 GearActuator_2 3 "NoAction" 2 "Reserved" 1 "On" 0 "Off" ;
VAL_ 2147548871 GearActuator_1 3 "NoAction" 2 "Reserved" 1 "On" 0 "Off" ;
VAL_ 2147548871 EngagementIndicator 3 "NoAction" 2 "Reserved" 1 "On" 0 "Off" ;
VAL_ 2147548871 DefuelActuator 3 "NoAction" 2 "Reserved" 1 "On" 0 "Off" ;
VAL_ 2147548871 ClutchActuator 3 "NoAction" 2 "Reserved" 1 "On" 0 "Off" ;
VAL_ 2147548871 CenterRailIndicator 3 "NoAction" 2 "Reserved" 1 "On" 0 "Off" ;
VAL_ 2147545090 TorqueConverterLockupEngaged 3 "NoAction" 2 "Reserved" 1 "Engage" 0 "Disengage" ;
VAL_ 2147545090 ShiftInProcess 3 "NotAvailable" 2 "Error" 1 "InProcess" 0 "NotInProcess" ;
VAL_ 2147545090 ProgressiveShiftDisable 3 "NoAction" 2 "Reserved" 1 "Disabled" 0 "NotDisabled" ;
VAL_ 2147545090 MomentaryEngineOverspeedEnable 3 "NoAction" 2 "Reserved" 1 "Enabled" 0 "Disabled" ;
VAL_ 2147545090 DrivelineEngaged 3 "NotAvailable" 2 "Error" 1 "Engage" 0 "Disengage" ;
VAL_ 2147548866 TransmissionOutputRetarder 3 "NoAction" 2 "Reserved" 1 "On" 0 "Off" ;
VAL_ 2147545088 RetarderEnableShiftAssistSwtch 3 "NotAvailable" 2 "Error" 1 "Enabled" 0 "Disabled" ;
VAL_ 2147545088 RetarderEnableBrakeAssistSwtch 3 "NotAvailable" 2 "Error" 1 "Enabled" 0 "Disabled" ;
VAL_ 2147545088 EngineRetarderTorqueMode 6 "Transmission" 5 "ASRcontrol" 4 "RoadSpeed" 3 "PTOGovernor" 2 "CruiseControl" 1 "AcceleratorPedal" 0 "NoRequest" ;
VAL_ 2147545091 APLowIdleSwitch 3 "NotAvailable" 2 "Error" 1 "Condition" 0 "NotCondition" ;
VAL_ 2147545091 APKickdownSwitch 3 "NotAvailable" 2 "Error" 1 "Active" 0 "Passive" ;
VAL_ 2147545092 EngineRetarderTorqueMode 6 "Transmission" 5 "ASRcontrol" 4 "RoadSpeed" 3 "PTOGovernor" 2 "CruiseControl" 1 "AcceleratorPedal" 0 "NoRequest" ;
VAL_ 2147545089 ASROffroadSwitch 3 "NotAvailable" 2 "Error" 1 "Active" 0 "Passive" ;
VAL_ 2147545089 ASRHillHolderSwitch 3 "NotAvailable" 2 "Error" 1 "Active" 0 "Passive" ;
VAL_ 2147545089 ASREngineCtrlActive 3 "NoAction" 2 "Reserved" 1 "Active" 0 "Passive" ;
VAL_ 2147545089 ASRBrakeCtrlActive 3 "NoAction" 2 "Reserved" 1 "Active" 0 "Passive" ;
VAL_ 2147545089 ABSOffroadSwitch 3 "NotAvailable" 2 "Error" 1 "Active" 0 "Passive" ;
VAL_ 2147545089 ABSActive 3 "NoAction" 2 "Reserved" 1 "Active" 0 "Passive" ;
VAL_ 2147545094 Location 255 "NotAvailable" ;
VAL_ 2147545094 DifferentialLockRearAxle2 3 "NoAction" 2 "Reserved" 1 "Engage" 0 "Disengage" ;
VAL_ 2147545094 DifferentialLockRearAxle1 3 "NoAction" 2 "Reserved" 1 "Engage" 0 "Disengage" ;
VAL_ 2147545094 DifferentialLockFrontAxle2 3 "NoAction" 2 "Reserved" 1 "Engage" 0 "Disengage" ;
VAL_ 2147545094 DifferentialLockFrontAxle1 3 "NoAction" 2 "Reserved" 1 "Engage" 0 "Disengage" ;
VAL_ 2147545094 DifferentialCentralRear 3 "NoAction" 2 "Reserved" 1 "Engage" 0 "Disengage" ;
VAL_ 2147545094 DifferentialCentralFront 3 "NoAction" 2 "Reserved" 1 "Engage" 0 "Disengage" ;
VAL_ 2147545094 DifferentialCentral 3 "NoAction" 2 "Reserved" 1 "Engage" 0 "Disengage" ;
VAL_ 2147548913 TwoSpeedAxleSwitch 3 "NotAvailable" 2 "Error" 1 "HighSpeedRange" 0 "LowSpeedRange" ;
VAL_ 2147548913 ParkingBrakeSwitch 3 "NotAvailable" 2 "Error" 1 "Set" 0 "NotSet" ;
VAL_ 2147548913 IdleIncrementSwitch 3 "NotAvailable" 2 "Error" 1 "On" 0 "Off" ;
VAL_ 2147548913 IdleDecrementSwitch 3 "NotAvailable" 2 "Error" 1 "On" 0 "Off" ;
VAL_ 2147548913 EngineTestModeSwitch 3 "NotAvailable" 2 "Error" 1 "On" 0 "Off" ;
VAL_ 2147548913 CruiseCtrlState 7 "NotAvailable" 6 "AccelerateOverride" 5 "Set" 4 "Resume" 3 "DecelerateCoast" 2 "Accelerate" 1 "Hold" 0 "OffDisabled" ;
VAL_ 2147548913 CruiseCtrlSetSwitch 3 "NotAvailable" 2 "Error" 1 "Set" 0 "NotSet" ;
VAL_ 2147548913 CruiseCtrlResumeSwitch 3 "NotAvailable" 2 "Error" 1 "Resume" 0 "NotResume" ;
VAL_ 2147548913 CruiseCtrlEnableSwitch 3 "NotAvailable" 2 "Error" 1 "Enabled" 0 "Disabled" ;
VAL_ 2147548913 CruiseCtrlCoastSwitch 3 "NotAvailable" 2 "Error" 1 "Coast" 0 "NotCoast" ;
VAL_ 2147548913 CruiseCtrlActive 3 "NotAvailable" 2 "Error" 1 "SwitchedOn" 0 "SwitchedOff" ;
VAL_ 2147548913 CruiseCtrlAccelerateSwitch 3 "NotAvailable" 2 "Error" 1 "Accelerate" 0 "NotAccelerate" ;
VAL_ 2147548913 ClutchSwitch 3 "NotAvailable" 2 "Error" 1 "PedalDepressed" 0 "PedalReleased" ;
VAL_ 2147548913 BrakeSwitch 3 "NotAvailable" 2 "Error" 1 "PedalDepressed" 0 "PedalReleased" ;
VAL_ 2147548922 ParkingBrakeActuator 3 "NotAvailable" 2 "Error" 1 "Active" 0 "Inactive" ;
VAL_ 2147548921 DriveAxleLocation 255 "NotAvailable" ;
VAL_ 2147548889 I_OChannel_9 3 "NotAvailable" 2 "Error" 1 "On" 0 "Off" ;
VAL_ 2147548889 I_OChannel_8 3 "NotAvailable" 2 "Error" 1 "On" 0 "Off" ;
VAL_ 2147548889 I_OChannel_7 3 "NotAvailable" 2 "Error" 1 "On" 0 "Off" ;
VAL_ 2147548889 I_OChannel_6 3 "NotAvailable" 2 "Error" 1 "On" 0 "Off" ;
VAL_ 2147548889 I_OChannel_5 3 "NotAvailable" 2 "Error" 1 "On" 0 "Off" ;
VAL_ 2147548889 I_OChannel_4 3 "NotAvailable" 2 "Error" 1 "On" 0 "Off" ;
VAL_ 2147548889 I_OChannel_3 3 "NotAvailable" 2 "Error" 1 "On" 0 "Off" ;
VAL_ 2147548889 I_OChannel_2 3 "NotAvailable" 2 "Error" 1 "On" 0 "Off" ;
VAL_ 2147548889 I_OChannel_16 3 "NotAvailable" 2 "Error" 1 "On" 0 "Off" ;
VAL_ 2147548889 I_OChannel_15 3 "NotAvailable" 2 "Error" 1 "On" 0 "Off" ;
VAL_ 2147548889 I_OChannel_14 3 "NotAvailable" 2 "Error" 1 "On" 0 "Off" ;
VAL_ 2147548889 I_OChannel_13 3 "NotAvailable" 2 "Error" 1 "On" 0 "Off" ;
VAL_ 2147548889 I_OChannel_12 3 "NotAvailable" 2 "Error" 1 "On" 0 "Off" ;
VAL_ 2147548889 I_OChannel_11 3 "NotAvailable" 2 "Error" 1 "On" 0 "Off" ;
VAL_ 2147548889 I_OChannel_10 3 "NotAvailable" 2 "Error" 1 "On" 0 "Off" ;
VAL_ 2147548889 I_OChannel_1 3 "NotAvailable" 2 "Error" 1 "On" 0 "Off" ;
VAL_ 2147543040 PGN 255 "NotAvailable" ;
VAL_ 2147543040 CtrlByte 32 "BAM" 255 "Abort" 19 "EoMACK" 17 "CTS" 16 "RTS" 1 "NACK" 0 "PACK" ;
